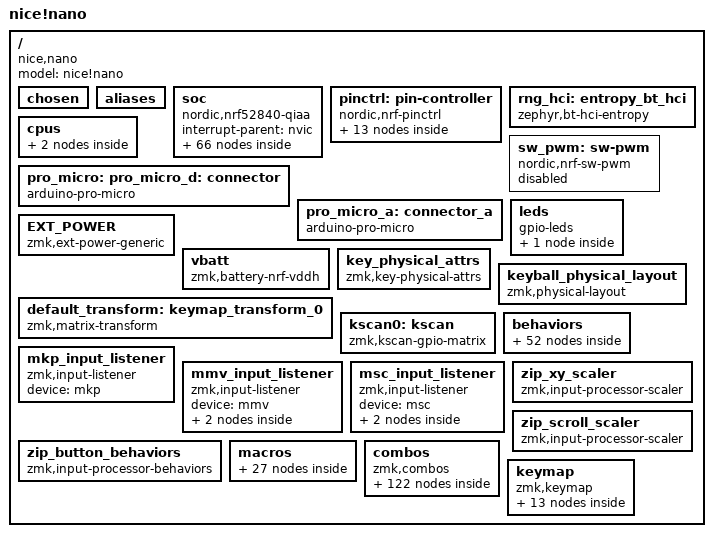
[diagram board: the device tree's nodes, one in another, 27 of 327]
/dts-v1/;

/ {
	#address-cells = < 0x1 >;
	#size-cells = < 0x1 >;
	model = "nice!nano";
	compatible = "nice,nano";
	chosen {
		zephyr,entropy = &rng;
		zephyr,flash-controller = &flash_controller;
		zephyr,code-partition = &code_partition;
		zephyr,sram = &sram0;
		zephyr,flash = &flash0;
		zmk,battery = &vbatt;
		zephyr,display = &oled;
		zmk,physical-layout = &keyball_physical_layout;
		zephyr,console = &snippet_zmk_usb_logging_uart;
		zephyr,shell-uart = &snippet_zmk_usb_logging_uart;
	};
	aliases {
	};
	soc {
		#address-cells = < 0x1 >;
		#size-cells = < 0x1 >;
		compatible = "nordic,nrf52840-qiaa", "nordic,nrf52840", "nordic,nrf52", "simple-bus";
		interrupt-parent = < &nvic >;
		ranges;
		nvic: interrupt-controller@e000e100 {
			#address-cells = < 0x1 >;
			compatible = "arm,v7m-nvic";
			reg = < 0xe000e100 0xc00 >;
			interrupt-controller;
			#interrupt-cells = < 0x2 >;
			arm,num-irq-priority-bits = < 0x3 >;
			phandle = < 0x1 >;
		};
		systick: timer@e000e010 {
			compatible = "arm,armv7m-systick";
			reg = < 0xe000e010 0x10 >;
			status = "disabled";
		};
		ficr: ficr@10000000 {
			compatible = "nordic,nrf-ficr";
			reg = < 0x10000000 0x1000 >;
			status = "okay";
		};
		uicr: uicr@10001000 {
			compatible = "nordic,nrf-uicr";
			reg = < 0x10001000 0x1000 >;
			status = "okay";
		};
		sram0: memory@20000000 {
			compatible = "mmio-sram";
			reg = < 0x20000000 0x40000 >;
		};
		clock: clock@40000000 {
			compatible = "nordic,nrf-clock";
			reg = < 0x40000000 0x1000 >;
			interrupts = < 0x0 0x1 >;
			status = "okay";
		};
		power: power@40000000 {
			compatible = "nordic,nrf-power";
			reg = < 0x40000000 0x1000 >;
			interrupts = < 0x0 0x1 >;
			status = "okay";
			#address-cells = < 0x1 >;
			#size-cells = < 0x1 >;
			gpregret1: gpregret1@4000051c {
				#address-cells = < 0x1 >;
				#size-cells = < 0x1 >;
				compatible = "nordic,nrf-gpregret";
				reg = < 0x4000051c 0x1 >;
				status = "okay";
			};
			gpregret2: gpregret2@40000520 {
				#address-cells = < 0x1 >;
				#size-cells = < 0x1 >;
				compatible = "nordic,nrf-gpregret";
				reg = < 0x40000520 0x1 >;
				status = "okay";
			};
		};
		radio: radio@40001000 {
			compatible = "nordic,nrf-radio";
			reg = < 0x40001000 0x1000 >;
			interrupts = < 0x1 0x1 >;
			status = "okay";
			ieee802154-supported;
			ble-2mbps-supported;
			ble-coded-phy-supported;
			tx-high-power-supported;
			ieee802154: ieee802154 {
				compatible = "nordic,nrf-ieee802154";
				status = "disabled";
			};
		};
		uart0: pro_micro_serial: uart@40002000 {
			compatible = "nordic,nrf-uarte";
			reg = < 0x40002000 0x1000 >;
			interrupts = < 0x2 0x1 >;
			status = "disabled";
			current-speed = < 0x1c200 >;
			pinctrl-0 = < &uart0_default >;
			pinctrl-1 = < &uart0_sleep >;
			pinctrl-names = "default", "sleep";
		};
		i2c0: pro_micro_i2c: i2c@40003000 {
			compatible = "nordic,nrf-twi";
			#address-cells = < 0x1 >;
			#size-cells = < 0x0 >;
			reg = < 0x40003000 0x1000 >;
			clock-frequency = < 0x186a0 >;
			interrupts = < 0x3 0x1 >;
			easydma-maxcnt-bits = < 0x10 >;
			status = "okay";
			pinctrl-0 = < &i2c0_default >;
			pinctrl-1 = < &i2c0_sleep >;
			pinctrl-names = "default", "sleep";
			oled: ssd1306@3c {
				compatible = "solomon,ssd1306fb";
				reg = < 0x3c >;
				width = < 0x80 >;
				height = < 0x20 >;
				segment-offset = < 0x0 >;
				page-offset = < 0x0 >;
				display-offset = < 0x0 >;
				multiplex-ratio = < 0x1f >;
				segment-remap;
				com-invdir;
				com-sequential;
				inversion-on;
				prechargep = < 0x22 >;
			};
		};
		spi0: spi@40003000 {
			compatible = "nordic,nrf-spim";
			#address-cells = < 0x1 >;
			#size-cells = < 0x0 >;
			reg = < 0x40003000 0x1000 >;
			interrupts = < 0x3 0x1 >;
			max-frequency = < 0x7a1200 >;
			easydma-maxcnt-bits = < 0x10 >;
			status = "disabled";
		};
		i2c1: i2c@40004000 {
			compatible = "nordic,nrf-twim";
			#address-cells = < 0x1 >;
			#size-cells = < 0x0 >;
			reg = < 0x40004000 0x1000 >;
			clock-frequency = < 0x186a0 >;
			interrupts = < 0x4 0x1 >;
			easydma-maxcnt-bits = < 0x10 >;
			status = "disabled";
		};
		spi1: pro_micro_spi: spi@40004000 {
			compatible = "nordic,nrf-spim";
			#address-cells = < 0x1 >;
			#size-cells = < 0x0 >;
			reg = < 0x40004000 0x1000 >;
			interrupts = < 0x4 0x1 >;
			max-frequency = < 0x7a1200 >;
			easydma-maxcnt-bits = < 0x10 >;
			status = "disabled";
			pinctrl-0 = < &spi1_default >;
			pinctrl-1 = < &spi1_sleep >;
			pinctrl-names = "default", "sleep";
		};
		nfct: nfct@40005000 {
			compatible = "nordic,nrf-nfct";
			reg = < 0x40005000 0x1000 >;
			interrupts = < 0x5 0x1 >;
			status = "okay";
		};
		gpiote: gpiote@40006000 {
			compatible = "nordic,nrf-gpiote";
			reg = < 0x40006000 0x1000 >;
			interrupts = < 0x6 0x5 >;
			status = "okay";
		};
		adc: adc@40007000 {
			compatible = "nordic,nrf-saadc";
			reg = < 0x40007000 0x1000 >;
			interrupts = < 0x7 0x1 >;
			status = "okay";
			#io-channel-cells = < 0x1 >;
		};
		timer0: timer@40008000 {
			compatible = "nordic,nrf-timer";
			status = "disabled";
			reg = < 0x40008000 0x1000 >;
			cc-num = < 0x4 >;
			max-bit-width = < 0x20 >;
			interrupts = < 0x8 0x1 >;
			prescaler = < 0x0 >;
		};
		timer1: timer@40009000 {
			compatible = "nordic,nrf-timer";
			status = "disabled";
			reg = < 0x40009000 0x1000 >;
			cc-num = < 0x4 >;
			max-bit-width = < 0x20 >;
			interrupts = < 0x9 0x1 >;
			prescaler = < 0x0 >;
			phandle = < 0x8 >;
		};
		timer2: timer@4000a000 {
			compatible = "nordic,nrf-timer";
			status = "disabled";
			reg = < 0x4000a000 0x1000 >;
			cc-num = < 0x4 >;
			max-bit-width = < 0x20 >;
			interrupts = < 0xa 0x1 >;
			prescaler = < 0x0 >;
		};
		rtc0: rtc@4000b000 {
			compatible = "nordic,nrf-rtc";
			reg = < 0x4000b000 0x1000 >;
			cc-num = < 0x3 >;
			interrupts = < 0xb 0x1 >;
			status = "disabled";
			clock-frequency = < 0x8000 >;
			prescaler = < 0x1 >;
		};
		temp: temp@4000c000 {
			compatible = "nordic,nrf-temp";
			reg = < 0x4000c000 0x1000 >;
			interrupts = < 0xc 0x1 >;
			status = "okay";
		};
		rng: random@4000d000 {
			compatible = "nordic,nrf-rng";
			reg = < 0x4000d000 0x1000 >;
			interrupts = < 0xd 0x1 >;
			status = "okay";
		};
		ecb: ecb@4000e000 {
			compatible = "nordic,nrf-ecb";
			reg = < 0x4000e000 0x1000 >;
			interrupts = < 0xe 0x1 >;
			status = "okay";
		};
		ccm: ccm@4000f000 {
			compatible = "nordic,nrf-ccm";
			reg = < 0x4000f000 0x1000 >;
			interrupts = < 0xf 0x1 >;
			length-field-length-8-bits;
			status = "okay";
		};
		wdt: wdt0: watchdog@40010000 {
			compatible = "nordic,nrf-wdt";
			reg = < 0x40010000 0x1000 >;
			interrupts = < 0x10 0x1 >;
			status = "okay";
		};
		rtc1: rtc@40011000 {
			compatible = "nordic,nrf-rtc";
			reg = < 0x40011000 0x1000 >;
			cc-num = < 0x4 >;
			interrupts = < 0x11 0x1 >;
			status = "disabled";
			clock-frequency = < 0x8000 >;
			prescaler = < 0x1 >;
		};
		qdec: qdec0: qdec@40012000 {
			compatible = "nordic,nrf-qdec";
			reg = < 0x40012000 0x1000 >;
			interrupts = < 0x12 0x1 >;
			status = "disabled";
		};
		comp: comparator@40013000 {
			compatible = "nordic,nrf-comp";
			reg = < 0x40013000 0x1000 >;
			interrupts = < 0x13 0x1 >;
			status = "disabled";
			#io-channel-cells = < 0x1 >;
		};
		egu0: swi0: egu@40014000 {
			compatible = "nordic,nrf-egu", "nordic,nrf-swi";
			reg = < 0x40014000 0x1000 >;
			interrupts = < 0x14 0x1 >;
			status = "okay";
		};
		egu1: swi1: egu@40015000 {
			compatible = "nordic,nrf-egu", "nordic,nrf-swi";
			reg = < 0x40015000 0x1000 >;
			interrupts = < 0x15 0x1 >;
			status = "okay";
		};
		egu2: swi2: egu@40016000 {
			compatible = "nordic,nrf-egu", "nordic,nrf-swi";
			reg = < 0x40016000 0x1000 >;
			interrupts = < 0x16 0x1 >;
			status = "okay";
		};
		egu3: swi3: egu@40017000 {
			compatible = "nordic,nrf-egu", "nordic,nrf-swi";
			reg = < 0x40017000 0x1000 >;
			interrupts = < 0x17 0x1 >;
			status = "okay";
		};
		egu4: swi4: egu@40018000 {
			compatible = "nordic,nrf-egu", "nordic,nrf-swi";
			reg = < 0x40018000 0x1000 >;
			interrupts = < 0x18 0x1 >;
			status = "okay";
		};
		egu5: swi5: egu@40019000 {
			compatible = "nordic,nrf-egu", "nordic,nrf-swi";
			reg = < 0x40019000 0x1000 >;
			interrupts = < 0x19 0x1 >;
			status = "okay";
		};
		timer3: timer@4001a000 {
			compatible = "nordic,nrf-timer";
			status = "disabled";
			reg = < 0x4001a000 0x1000 >;
			cc-num = < 0x6 >;
			max-bit-width = < 0x20 >;
			interrupts = < 0x1a 0x1 >;
			prescaler = < 0x0 >;
		};
		timer4: timer@4001b000 {
			compatible = "nordic,nrf-timer";
			status = "disabled";
			reg = < 0x4001b000 0x1000 >;
			cc-num = < 0x6 >;
			max-bit-width = < 0x20 >;
			interrupts = < 0x1b 0x1 >;
			prescaler = < 0x0 >;
		};
		pwm0: pwm@4001c000 {
			compatible = "nordic,nrf-pwm";
			reg = < 0x4001c000 0x1000 >;
			interrupts = < 0x1c 0x1 >;
			status = "disabled";
			#pwm-cells = < 0x3 >;
		};
		pdm0: pdm@4001d000 {
			compatible = "nordic,nrf-pdm";
			reg = < 0x4001d000 0x1000 >;
			interrupts = < 0x1d 0x1 >;
			status = "disabled";
		};
		acl: acl@4001e000 {
			compatible = "nordic,nrf-acl";
			reg = < 0x4001e000 0x1000 >;
			status = "okay";
		};
		flash_controller: flash-controller@4001e000 {
			compatible = "nordic,nrf52-flash-controller";
			reg = < 0x4001e000 0x1000 >;
			partial-erase;
			#address-cells = < 0x1 >;
			#size-cells = < 0x1 >;
			flash0: flash@0 {
				compatible = "soc-nv-flash";
				erase-block-size = < 0x1000 >;
				write-block-size = < 0x4 >;
				reg = < 0x0 0x100000 >;
				partitions {
					compatible = "fixed-partitions";
					#address-cells = < 0x1 >;
					#size-cells = < 0x1 >;
					sd_partition: partition@0 {
						reg = < 0x0 0x26000 >;
					};
					code_partition: partition@26000 {
						reg = < 0x26000 0xc6000 >;
					};
					storage_partition: partition@ec000 {
						reg = < 0xec000 0x8000 >;
					};
					boot_partition: partition@f4000 {
						reg = < 0xf4000 0xc000 >;
					};
				};
			};
		};
		ppi: ppi@4001f000 {
			compatible = "nordic,nrf-ppi";
			reg = < 0x4001f000 0x1000 >;
			status = "okay";
		};
		mwu: mwu@40020000 {
			compatible = "nordic,nrf-mwu";
			reg = < 0x40020000 0x1000 >;
			status = "okay";
		};
		pwm1: pwm@40021000 {
			compatible = "nordic,nrf-pwm";
			reg = < 0x40021000 0x1000 >;
			interrupts = < 0x21 0x1 >;
			status = "disabled";
			#pwm-cells = < 0x3 >;
		};
		pwm2: pwm@40022000 {
			compatible = "nordic,nrf-pwm";
			reg = < 0x40022000 0x1000 >;
			interrupts = < 0x22 0x1 >;
			status = "disabled";
			#pwm-cells = < 0x3 >;
		};
		spi2: spi@40023000 {
			compatible = "nordic,nrf-spim";
			#address-cells = < 0x1 >;
			#size-cells = < 0x0 >;
			reg = < 0x40023000 0x1000 >;
			interrupts = < 0x23 0x1 >;
			max-frequency = < 0x7a1200 >;
			easydma-maxcnt-bits = < 0x10 >;
			status = "disabled";
		};
		rtc2: rtc@40024000 {
			compatible = "nordic,nrf-rtc";
			reg = < 0x40024000 0x1000 >;
			cc-num = < 0x4 >;
			interrupts = < 0x24 0x1 >;
			status = "disabled";
			clock-frequency = < 0x8000 >;
			prescaler = < 0x1 >;
		};
		i2s0: i2s@40025000 {
			compatible = "nordic,nrf-i2s";
			#address-cells = < 0x1 >;
			#size-cells = < 0x0 >;
			reg = < 0x40025000 0x1000 >;
			interrupts = < 0x25 0x1 >;
			status = "disabled";
		};
		usbd: zephyr_udc0: usbd@40027000 {
			compatible = "nordic,nrf-usbd";
			reg = < 0x40027000 0x1000 >;
			interrupts = < 0x27 0x1 >;
			num-bidir-endpoints = < 0x1 >;
			num-in-endpoints = < 0x7 >;
			num-out-endpoints = < 0x7 >;
			num-isoin-endpoints = < 0x1 >;
			num-isoout-endpoints = < 0x1 >;
			status = "okay";
			snippet_zmk_usb_logging_uart: snippet_zmk_usb_logging_uart {
				compatible = "zephyr,cdc-acm-uart";
			};
		};
		uart1: uart@40028000 {
			compatible = "nordic,nrf-uarte";
			reg = < 0x40028000 0x1000 >;
			interrupts = < 0x28 0x1 >;
			status = "disabled";
		};
		qspi: qspi@40029000 {
			compatible = "nordic,nrf-qspi";
			#address-cells = < 0x1 >;
			#size-cells = < 0x0 >;
			reg = < 0x40029000 0x1000 >, < 0x12000000 0x8000000 >;
			reg-names = "qspi", "qspi_mm";
			interrupts = < 0x29 0x1 >;
			status = "disabled";
		};
		pwm3: pwm@4002d000 {
			compatible = "nordic,nrf-pwm";
			reg = < 0x4002d000 0x1000 >;
			interrupts = < 0x2d 0x1 >;
			status = "disabled";
			#pwm-cells = < 0x3 >;
		};
		spi3: spi@4002f000 {
			compatible = "nordic,nrf-spim";
			#address-cells = < 0x1 >;
			#size-cells = < 0x0 >;
			reg = < 0x4002f000 0x1000 >;
			interrupts = < 0x2f 0x1 >;
			max-frequency = < 0x1e84800 >;
			easydma-maxcnt-bits = < 0x10 >;
			rx-delay-supported;
			rx-delay = < 0x2 >;
			status = "disabled";
		};
		gpio0: gpio@50000000 {
			compatible = "nordic,nrf-gpio";
			gpio-controller;
			reg = < 0x50000000 0x200 0x50000500 0x300 >;
			#gpio-cells = < 0x2 >;
			status = "okay";
			port = < 0x0 >;
			phandle = < 0x9 >;
		};
		gpio1: gpio@50000300 {
			compatible = "nordic,nrf-gpio";
			gpio-controller;
			reg = < 0x50000300 0x200 0x50000800 0x300 >;
			#gpio-cells = < 0x2 >;
			ngpios = < 0x10 >;
			status = "okay";
			port = < 0x1 >;
			phandle = < 0xa >;
		};
		cryptocell: crypto@5002a000 {
			compatible = "nordic,cryptocell", "arm,cryptocell-310";
			reg = < 0x5002a000 0x1000 >, < 0x5002b000 0x1000 >;
			reg-names = "wrapper", "core";
			interrupts = < 0x2a 0x1 >;
			status = "disabled";
		};
	};
	pinctrl: pin-controller {
		compatible = "nordic,nrf-pinctrl";
		uart0_default: uart0_default {
			phandle = < 0x2 >;
			group1 {
				psels = < 0x10008 >;
				bias-pull-up;
			};
			group2 {
				psels = < 0x6 >;
			};
		};
		uart0_sleep: uart0_sleep {
			phandle = < 0x3 >;
			group1 {
				psels = < 0x10008 >, < 0x6 >;
				low-power-enable;
			};
		};
		i2c0_default: i2c0_default {
			phandle = < 0x4 >;
			group1 {
				psels = < 0xc0011 >, < 0xb0014 >;
			};
		};
		i2c0_sleep: i2c0_sleep {
			phandle = < 0x5 >;
			group1 {
				psels = < 0xc0011 >, < 0xb0014 >;
				low-power-enable;
			};
		};
		spi1_default: spi1_default {
			phandle = < 0x6 >;
			group1 {
				psels = < 0x4002d >, < 0x5000a >, < 0x6002b >;
			};
		};
		spi1_sleep: spi1_sleep {
			phandle = < 0x7 >;
			group1 {
				psels = < 0x4002d >, < 0x5000a >, < 0x6002b >;
				low-power-enable;
			};
		};
	};
	rng_hci: entropy_bt_hci {
		compatible = "zephyr,bt-hci-entropy";
		status = "okay";
	};
	sw_pwm: sw-pwm {
		compatible = "nordic,nrf-sw-pwm";
		status = "disabled";
		generator = < &timer1 >;
		clock-prescaler = < 0x0 >;
		#pwm-cells = < 0x3 >;
	};
	cpus {
		#address-cells = < 0x1 >;
		#size-cells = < 0x0 >;
		cpu@0 {
			device_type = "cpu";
			compatible = "arm,cortex-m4f";
			reg = < 0x0 >;
			#address-cells = < 0x1 >;
			#size-cells = < 0x1 >;
			itm: itm@e0000000 {
				compatible = "arm,armv7m-itm";
				reg = < 0xe0000000 0x1000 >;
				swo-ref-frequency = < 0x1e84800 >;
			};
		};
	};
	pro_micro: pro_micro_d: connector {
		compatible = "arduino-pro-micro";
		#gpio-cells = < 0x2 >;
		gpio-map-mask = < 0xffffffff 0xffffffc0 >;
		gpio-map-pass-thru = < 0x0 0x3f >;
		gpio-map = < 0x0 0x0 &gpio0 0x8 0x0 >, < 0x1 0x0 &gpio0 0x6 0x0 >, < 0x2 0x0 &gpio0 0x11 0x0 >, < 0x3 0x0 &gpio0 0x14 0x0 >, < 0x4 0x0 &gpio0 0x16 0x0 >, < 0x5 0x0 &gpio0 0x18 0x0 >, < 0x6 0x0 &gpio1 0x0 0x0 >, < 0x7 0x0 &gpio0 0xb 0x0 >, < 0x8 0x0 &gpio1 0x4 0x0 >, < 0x9 0x0 &gpio1 0x6 0x0 >, < 0xa 0x0 &gpio0 0x9 0x0 >, < 0x10 0x0 &gpio0 0xa 0x0 >, < 0xe 0x0 &gpio1 0xb 0x0 >, < 0xf 0x0 &gpio1 0xd 0x0 >, < 0x12 0x0 &gpio1 0xf 0x0 >, < 0x13 0x0 &gpio0 0x2 0x0 >, < 0x14 0x0 &gpio0 0x1d 0x0 >, < 0x15 0x0 &gpio0 0x1f 0x0 >;
		phandle = < 0xe >;
	};
	pro_micro_a: connector_a {
		compatible = "arduino-pro-micro";
		#gpio-cells = < 0x2 >;
		gpio-map-mask = < 0xffffffff 0xffffffc0 >;
		gpio-map-pass-thru = < 0x0 0x3f >;
		gpio-map = < 0x0 0x0 &gpio1 0xf 0x0 >, < 0x1 0x0 &gpio0 0x2 0x0 >, < 0x2 0x0 &gpio0 0x1d 0x0 >, < 0x3 0x0 &gpio0 0x1f 0x0 >, < 0x6 0x0 &gpio0 0x16 0x0 >, < 0x7 0x0 &gpio1 0x0 0x0 >, < 0x8 0x0 &gpio1 0x4 0x0 >, < 0x9 0x0 &gpio1 0x6 0x0 >, < 0xa 0x0 &gpio0 0x9 0x0 >;
	};
	leds {
		compatible = "gpio-leds";
		blue_led: led_0 {
			gpios = < &gpio0 0xf 0x0 >;
		};
	};
	EXT_POWER {
		compatible = "zmk,ext-power-generic";
		control-gpios = < &gpio0 0xd 0x0 >;
		init-delay-ms = < 0x32 >;
	};
	vbatt: vbatt {
		compatible = "zmk,battery-nrf-vddh";
	};
	key_physical_attrs: key_physical_attrs {
		compatible = "zmk,key-physical-attrs";
		#key-cells = < 0x7 >;
		phandle = < 0xd >;
	};
	keyball_physical_layout: keyball_physical_layout {
		compatible = "zmk,physical-layout";
		display-name = "Default";
		transform = < &default_transform >;
		kscan = < &kscan0 >;
		keys = < &key_physical_attrs 0x64 0x64 0x0 0x26 0x0 0x0 0x0 >, < &key_physical_attrs 0x64 0x64 0x64 0xd 0x0 0x0 0x0 >, < &key_physical_attrs 0x64 0x64 0xc8 0x0 0x0 0x0 0x0 >, < &key_physical_attrs 0x64 0x64 0x12c 0xd 0x0 0x0 0x0 >, < &key_physical_attrs 0x64 0x64 0x190 0x19 0x0 0x0 0x0 >, < &key_physical_attrs 0x64 0x64 0x352 0x19 0x0 0x0 0x0 >, < &key_physical_attrs 0x64 0x64 0x3b6 0xd 0x0 0x0 0x0 >, < &key_physical_attrs 0x64 0x64 0x41a 0x0 0x0 0x0 0x0 >, < &key_physical_attrs 0x64 0x64 0x47e 0xd 0x0 0x0 0x0 >, < &key_physical_attrs 0x64 0x64 0x4e2 0x26 0x0 0x0 0x0 >, < &key_physical_attrs 0x64 0x64 0x0 0x8a 0x0 0x0 0x0 >, < &key_physical_attrs 0x64 0x64 0x64 0x71 0x0 0x0 0x0 >, < &key_physical_attrs 0x64 0x64 0xc8 0x64 0x0 0x0 0x0 >, < &key_physical_attrs 0x64 0x64 0x12c 0x71 0x0 0x0 0x0 >, < &key_physical_attrs 0x64 0x64 0x190 0x7d 0x0 0x0 0x0 >, < &key_physical_attrs 0x64 0x64 0x352 0x7d 0x0 0x0 0x0 >, < &key_physical_attrs 0x64 0x64 0x3b6 0x71 0x0 0x0 0x0 >, < &key_physical_attrs 0x64 0x64 0x41a 0x64 0x0 0x0 0x0 >, < &key_physical_attrs 0x64 0x64 0x47e 0x71 0x0 0x0 0x0 >, < &key_physical_attrs 0x64 0x64 0x4e2 0x8a 0x0 0x0 0x0 >, < &key_physical_attrs 0x64 0x64 0x0 0xee 0x0 0x0 0x0 >, < &key_physical_attrs 0x64 0x64 0x64 0xd5 0x0 0x0 0x0 >, < &key_physical_attrs 0x64 0x64 0xc8 0xc8 0x0 0x0 0x0 >, < &key_physical_attrs 0x64 0x64 0x12c 0xd5 0x0 0x0 0x0 >, < &key_physical_attrs 0x64 0x64 0x190 0xe1 0x0 0x0 0x0 >, < &key_physical_attrs 0x64 0x64 0x352 0xe1 0x0 0x0 0x0 >, < &key_physical_attrs 0x64 0x64 0x3b6 0xd5 0x0 0x0 0x0 >, < &key_physical_attrs 0x64 0x64 0x41a 0xc8 0x0 0x0 0x0 >, < &key_physical_attrs 0x64 0x64 0x47e 0xd5 0x0 0x0 0x0 >, < &key_physical_attrs 0x64 0x64 0x4e2 0xee 0x0 0x0 0x0 >, < &key_physical_attrs 0x64 0x64 0x0 0x152 0x0 0x0 0x0 >, < &key_physical_attrs 0x64 0x64 0x64 0x139 0x0 0x0 0x0 >, < &key_physical_attrs 0x64 0x64 0xc8 0x12c 0x0 0x0 0x0 >, < &key_physical_attrs 0x64 0x64 0x145 0x15e 0x0 0x0 0x0 >, < &key_physical_attrs 0x64 0x64 0x1fe 0x104 0x3e8 0xffffffce 0xffffff9c >, < &key_physical_attrs 0x64 0x64 0x46 0xd2 0x9c4 0xffffffce 0x578 >, < &key_physical_attrs 0x64 0x64 0x44c 0x36b 0xfffff5d8 0xffffffce 0x578 >, < &key_physical_attrs 0x64 0x64 0x307 0x20d 0xfffffc18 0xffffffce 0xffffff9c >, < &key_physical_attrs 0x64 0x64 0x4e2 0x152 0x0 0x0 0x0 >;
	};
	default_transform: keymap_transform_0 {
		compatible = "zmk,matrix-transform";
		columns = < 0xc >;
		rows = < 0x4 >;
		map = < 0x0 0x1 0x2 0x3 0x4 0xa 0x9 0x8 0x7 0x6 0x100 0x101 0x102 0x103 0x104 0x10a 0x109 0x108 0x107 0x106 0x200 0x201 0x202 0x203 0x204 0x20a 0x209 0x208 0x207 0x206 0x300 0x301 0x302 0x303 0x304 0x305 0x30b 0x30a 0x306 >;
		phandle = < 0xb >;
	};
	kscan0: kscan {
		compatible = "zmk,kscan-gpio-matrix";
		label = "KSCAN";
		diode-direction = "col2row";
		row-gpios = < &pro_micro 0x15 0x20 >, < &pro_micro 0x14 0x20 >, < &pro_micro 0x13 0x20 >, < &pro_micro 0x12 0x20 >;
		col-gpios = < &pro_micro 0x4 0x0 >, < &pro_micro 0x5 0x0 >, < &pro_micro 0x6 0x0 >, < &pro_micro 0x7 0x0 >, < &pro_micro 0x8 0x0 >, < &pro_micro 0x9 0x0 >;
		phandle = < 0xc >;
	};
	behaviors {
		mkp: mouse_key_press {
			compatible = "zmk,behavior-mouse-key-press";
			#binding-cells = < 0x1 >;
			display-name = "Mouse Key Press";
			phandle = < 0x21 >;
		};
		mmv: mouse_move {
			compatible = "zmk,behavior-input-two-axis";
			#binding-cells = < 0x1 >;
			x-input-code = < 0x0 >;
			y-input-code = < 0x1 >;
			time-to-max-speed-ms = < 0x1f4 >;
			acceleration-exponent = < 0x1 >;
			delay-ms = < 0x0 >;
			phandle = < 0x22 >;
		};
		msc: mouse_scroll {
			compatible = "zmk,behavior-input-two-axis";
			#binding-cells = < 0x1 >;
			x-input-code = < 0x6 >;
			y-input-code = < 0x8 >;
			time-to-max-speed-ms = < 0x12c >;
			acceleration-exponent = < 0x0 >;
			delay-ms = < 0x0 >;
			phandle = < 0x24 >;
		};
		kp: key_press {
			compatible = "zmk,behavior-key-press";
			#binding-cells = < 0x1 >;
			display-name = "Key Press";
			phandle = < 0xf >;
		};
		trans: transparent {
			compatible = "zmk,behavior-transparent";
			#binding-cells = < 0x0 >;
			display-name = "Transparent";
			phandle = < 0x42 >;
		};
		none: none {
			compatible = "zmk,behavior-none";
			#binding-cells = < 0x0 >;
			display-name = "None";
			phandle = < 0x20 >;
		};
		sk: sticky_key {
			compatible = "zmk,behavior-sticky-key";
			#binding-cells = < 0x1 >;
			release-after-ms = < 0x3e8 >;
			bindings = < &kp >;
			ignore-modifiers;
			display-name = "Sticky Key";
			phandle = < 0x2c >;
		};
		sl: sticky_layer {
			compatible = "zmk,behavior-sticky-key";
			#binding-cells = < 0x1 >;
			release-after-ms = < 0x3e8 >;
			bindings = < &mo >;
			quick-release;
			display-name = "Sticky Layer";
			phandle = < 0x1a >;
		};
		mo: momentary_layer {
			compatible = "zmk,behavior-momentary-layer";
			#binding-cells = < 0x1 >;
			display-name = "Momentary Layer";
			phandle = < 0x10 >;
		};
		sys_reset: sysreset {
			compatible = "zmk,behavior-reset";
			#binding-cells = < 0x0 >;
			display-name = "Reset";
			phandle = < 0x50 >;
		};
		bootloader: bootload {
			compatible = "zmk,behavior-reset";
			type = < 0x57 >;
			#binding-cells = < 0x0 >;
			display-name = "Bootloader";
		};
		rgb_ug: rgb_ug {
			compatible = "zmk,behavior-rgb-underglow";
			#binding-cells = < 0x2 >;
			display-name = "Underglow";
		};
		bt: bluetooth {
			compatible = "zmk,behavior-bluetooth";
			#binding-cells = < 0x2 >;
			display-name = "Bluetooth";
			phandle = < 0x30 >;
		};
		ext_power: extpower {
			compatible = "zmk,behavior-ext-power";
			#binding-cells = < 0x1 >;
			display-name = "External Power";
		};
		out: outputs {
			compatible = "zmk,behavior-outputs";
			#binding-cells = < 0x1 >;
			display-name = "Output Selection";
			phandle = < 0x12 >;
		};
		caps_word: caps_word {
			compatible = "zmk,behavior-caps-word";
			#binding-cells = < 0x0 >;
			continue-list = < 0x207002d 0x7002d >;
			display-name = "Caps Word";
			phandle = < 0x3b >;
		};
		macro_tap: macro_tap {
			compatible = "zmk,macro-control-mode-tap";
			#binding-cells = < 0x0 >;
			phandle = < 0x27 >;
		};
		macro_press: macro_press {
			compatible = "zmk,macro-control-mode-press";
			#binding-cells = < 0x0 >;
			phandle = < 0x2b >;
		};
		macro_release: macro_release {
			compatible = "zmk,macro-control-mode-release";
			#binding-cells = < 0x0 >;
			phandle = < 0x2e >;
		};
		macro_tap_time: macro_tap_time {
			compatible = "zmk,macro-control-tap-time";
			#binding-cells = < 0x1 >;
			phandle = < 0x26 >;
		};
		macro_wait_time: macro_wait_time {
			compatible = "zmk,macro-control-wait-time";
			#binding-cells = < 0x1 >;
			phandle = < 0x2f >;
		};
		macro_pause_for_release: macro_pause_for_release {
			compatible = "zmk,macro-pause-for-release";
			#binding-cells = < 0x0 >;
			phandle = < 0x2d >;
		};
		macro_param_1to1: macro_param_1to1 {
			compatible = "zmk,macro-param-1to1";
			#binding-cells = < 0x0 >;
			phandle = < 0x28 >;
		};
		macro_param_1to2: macro_param_1to2 {
			compatible = "zmk,macro-param-1to2";
			#binding-cells = < 0x0 >;
			phandle = < 0x37 >;
		};
		macro_param_2to1: macro_param_2to1 {
			compatible = "zmk,macro-param-2to1";
			#binding-cells = < 0x0 >;
			phandle = < 0x29 >;
		};
		macro_param_2to2: macro_param_2to2 {
			compatible = "zmk,macro-param-2to2";
			#binding-cells = < 0x0 >;
		};
		studio_unlock: studio_unlock {
			compatible = "zmk,behavior-studio-unlock";
			#binding-cells = < 0x0 >;
			display-name = "Studio Unlock";
		};
		hml: home_row_mod_left {
			compatible = "zmk,behavior-hold-tap";
			#binding-cells = < 0x2 >;
			flavor = "balanced";
			tapping-term-ms = < 0x140 >;
			quick-tap-ms = < 0xaf >;
			require-prior-idle-ms = < 0xfa >;
			bindings = < &kp >, < &kp >;
			hold-trigger-key-positions = < 0x5 0x6 0x7 0x8 0x9 0xf 0x10 0x11 0x12 0x13 0x19 0x1a 0x1b 0x1c 0x1d 0x1e 0x1f 0x20 0x21 0x22 0x23 0x24 0x25 0x26 >;
			hold-trigger-on-release;
			phandle = < 0x40 >;
		};
		hmr: home_row_mod_right {
			compatible = "zmk,behavior-hold-tap";
			#binding-cells = < 0x2 >;
			flavor = "balanced";
			tapping-term-ms = < 0x140 >;
			quick-tap-ms = < 0xaf >;
			require-prior-idle-ms = < 0xfa >;
			bindings = < &kp >, < &kp >;
			hold-trigger-key-positions = < 0x0 0x1 0x2 0x3 0x4 0xa 0xb 0xc 0xd 0xe 0x14 0x15 0x16 0x17 0x18 0x1e 0x1f 0x20 0x21 0x22 0x23 0x24 0x25 0x26 >;
			hold-trigger-on-release;
			phandle = < 0x41 >;
		};
		bt_0: bt_0 {
			compatible = "zmk,behavior-tap-dance";
			label = "BT_0";
			#binding-cells = < 0x0 >;
			tapping-term-ms = < 0x3e8 >;
			bindings = < &bt_select_disc_0 >, < &out 0x1 >, < &bt_pairing_c 0x0 >;
			phandle = < 0x4b >;
		};
		bt_1: bt_1 {
			compatible = "zmk,behavior-tap-dance";
			label = "BT_1";
			#binding-cells = < 0x0 >;
			tapping-term-ms = < 0x3e8 >;
			bindings = < &bt_select_disc_1 >, < &out 0x1 >, < &bt_pairing_c 0x1 >;
			phandle = < 0x4c >;
		};
		bt_2: bt_2 {
			compatible = "zmk,behavior-tap-dance";
			label = "BT_2";
			#binding-cells = < 0x0 >;
			tapping-term-ms = < 0x3e8 >;
			bindings = < &bt_select_disc_2 >, < &out 0x1 >, < &bt_pairing_c 0x2 >;
			phandle = < 0x4d >;
		};
		bt_3: bt_3 {
			compatible = "zmk,behavior-tap-dance";
			label = "BT_3";
			#binding-cells = < 0x0 >;
			tapping-term-ms = < 0x3e8 >;
			bindings = < &bt_select_disc_3 >, < &out 0x1 >, < &bt_pairing_c 0x3 >;
			phandle = < 0x4e >;
		};
		bt_4: bt_4 {
			compatible = "zmk,behavior-tap-dance";
			label = "BT_4";
			#binding-cells = < 0x0 >;
			tapping-term-ms = < 0x3e8 >;
			bindings = < &bt_select_disc_4 >, < &out 0x1 >, < &bt_pairing_c 0x4 >;
			phandle = < 0x4f >;
		};
		tog_on: toggle_layer_on_only {
			compatible = "zmk,behavior-toggle-layer";
			#binding-cells = < 0x1 >;
			display-name = "Toggle Layer On";
			toggle-mode = "on";
			phandle = < 0x39 >;
		};
		tog_off: toggle_layer_off_only {
			compatible = "zmk,behavior-toggle-layer";
			#binding-cells = < 0x1 >;
			display-name = "Toggle Layer Off";
			toggle-mode = "off";
			phandle = < 0x38 >;
		};
		tdSelectCoppingLR: tdSelectCoppingLR {
			compatible = "zmk,behavior-hold-tap";
			#binding-cells = < 0x2 >;
			tapping_term_ms = < 0xc8 >;
			quick_tap_ms = < 0x0 >;
			flavor = "tap-preferred";
			bindings = < &scl_l_to_r >, < &scw_l_to_r >;
			phandle = < 0x4a >;
		};
		lrlMo: lrlMo {
			compatible = "zmk,behavior-hold-tap";
			label = "LRLMO";
			bindings = < &kp >, < &kp >;
			#binding-cells = < 0x2 >;
			flavor = "balanced";
			tapping-term-ms = < 0xdc >;
			quick-tap-ms = < 0xaf >;
			phandle = < 0x3f >;
		};
		lrDl: lrDl {
			compatible = "zmk,behavior-hold-tap";
			label = "LRDL";
			bindings = < &kp >, < &kp >;
			#binding-cells = < 0x2 >;
			flavor = "balanced";
			require-prior-idle-ms = < 0x78 >;
			tapping-term-ms = < 0xdc >;
			quick-tap-ms = < 0xaf >;
		};
		lrrMo: lrrMo {
			compatible = "zmk,behavior-hold-tap";
			label = "LRRMO";
			bindings = < &kp >, < &kp >;
			#binding-cells = < 0x2 >;
			tapping-term-ms = < 0xdc >;
			quick-tap-ms = < 0xaf >;
			phandle = < 0x49 >;
		};
		base_th_mo_kp_hp: base_th_mo_kp_hp {
			compatible = "zmk,behavior-hold-tap";
			flavor = "hold-preferred";
			tapping-term-ms = < 0xdc >;
			hold-trigger-on-release;
			#binding-cells = < 0x2 >;
			bindings = < &mo >, < &kp >;
			phandle = < 0x44 >;
		};
		th_mo_kp_hp: th_mo_kp_hp {
			compatible = "zmk,behavior-hold-tap";
			flavor = "hold-preferred";
			tapping-term-ms = < 0xdc >;
			quick-tap-ms = < 0xbe >;
			hold-trigger-on-release;
			#binding-cells = < 0x2 >;
			bindings = < &mo >, < &kp >;
			phandle = < 0x47 >;
		};
		th_kp_kp_hp: th_kp_kp_hp {
			compatible = "zmk,behavior-hold-tap";
			flavor = "hold-preferred";
			tapping-term-ms = < 0xdc >;
			quick-tap-ms = < 0xbe >;
			#binding-cells = < 0x2 >;
			hold-trigger-on-release;
			bindings = < &kp >, < &kp >;
			phandle = < 0x46 >;
		};
		space: space {
			compatible = "zmk,behavior-hold-tap";
			flavor = "balanced";
			tapping-term-ms = < 0xdc >;
			#binding-cells = < 0x2 >;
			require-prior-idle-ms = < 0x50 >;
			bindings = < &mo >, < &kp >;
			phandle = < 0x48 >;
		};
		spacelm: thumb_layer_access_spacebarlm {
			compatible = "zmk,behavior-hold-tap";
			flavor = "balanced";
			tapping-term-ms = < 0xdc >;
			#binding-cells = < 0x2 >;
			require-prior-idle-ms = < 0x50 >;
			bindings = < &mo >, < &kp >;
			phandle = < 0x45 >;
		};
		th_kp_sl_hp: th_kp_sl_hp {
			compatible = "zmk,behavior-hold-tap";
			#binding-cells = < 0x2 >;
			tapping-term-ms = < 0xc8 >;
			flavor = "hold-preferred";
			bindings = < &kp >, < &sl >;
		};
		lm_homerow: lm_homerow {
			compatible = "zmk,behavior-hold-tap";
			flavor = "hold-preferred";
			tapping-term-ms = < 0xdc >;
			#binding-cells = < 0x2 >;
			bindings = < &mhr >, < &kp >;
		};
		lm_homerow_short: lm_homerow_short {
			compatible = "zmk,behavior-hold-tap";
			flavor = "hold-preferred";
			tapping-term-ms = < 0x96 >;
			#binding-cells = < 0x2 >;
			bindings = < &mhr >, < &kp >;
			phandle = < 0x43 >;
		};
		tdSelectCoppingRL: tdSelectCoppingRL {
			compatible = "zmk,behavior-hold-tap";
			#binding-cells = < 0x2 >;
			tapping_term_ms = < 0xc8 >;
			quick_tap_ms = < 0x0 >;
			flavor = "tap-preferred";
			bindings = < &scl_r_to_l >, < &scw_r_to_l >;
		};
		td_find_s_ht: td_find_s_ht {
			compatible = "zmk,behavior-hold-tap";
			#binding-cells = < 0x2 >;
			tapping_term_ms = < 0xc8 >;
			quick_tap_ms = < 0x0 >;
			flavor = "tap-preferred";
			bindings = < &pfind >, < &kp >;
			phandle = < 0x3d >;
		};
		td_find_g_ht: td_find_g_ht {
			compatible = "zmk,behavior-hold-tap";
			#binding-cells = < 0x2 >;
			tapping_term_ms = < 0xc8 >;
			quick_tap_ms = < 0x0 >;
			flavor = "tap-preferred";
			bindings = < &gpfind >, < &kp >;
			phandle = < 0x3e >;
		};
		nav_esc: nav_esc {
			compatible = "zmk,behavior-tap-dance";
			label = "NAV_ESC";
			#binding-cells = < 0x0 >;
			tapping-term-ms = < 0x1f4 >;
			bindings = < &mo 0x4 >, < &none >, < &kp 0x70029 >;
		};
	};
	mkp_input_listener: mkp_input_listener {
		compatible = "zmk,input-listener";
		device = < &mkp >;
	};
	mmv_input_listener: mmv_input_listener {
		compatible = "zmk,input-listener";
		device = < &mmv >;
		warp {
			layers = < 0x4 >;
			input-processors = < &zip_xy_scaler 0x3 0x1 >;
		};
		precision {
			layers = < 0x3 >;
			input-processors = < &zip_xy_scaler 0x1 0x2 >;
		};
	};
	msc_input_listener: msc_input_listener {
		compatible = "zmk,input-listener";
		device = < &msc >;
		warp {
			layers = < 0x4 >;
			input-processors = < &zip_scroll_scaler 0x2 0x1 >;
		};
		precision {
			layers = < 0x3 >;
			input-processors = < &zip_scroll_scaler 0x1 0x2 >;
		};
	};
	zip_xy_scaler: zip_xy_scaler {
		compatible = "zmk,input-processor-scaler";
		#input-processor-cells = < 0x2 >;
		type = < 0x2 >;
		codes = < 0x0 0x1 >;
		track-remainders;
		phandle = < 0x23 >;
	};
	zip_scroll_scaler: zip_scroll_scaler {
		compatible = "zmk,input-processor-scaler";
		#input-processor-cells = < 0x2 >;
		type = < 0x2 >;
		codes = < 0x8 0x6 >;
		track-remainders;
		phandle = < 0x25 >;
	};
	zip_button_behaviors: zip_button_behaviors {
		compatible = "zmk,input-processor-behaviors";
		#input-processor-cells = < 0x0 >;
		codes = < 0x100 0x101 0x102 >;
		bindings = < &none &none &none >;
	};
	macros {
		mc_sleep: mc_sleep {
			compatible = "zmk,behavior-macro";
			#binding-cells = < 0x0 >;
			bindings = < &macro_tap_time 0x3e8 >, < &kp 0x9070014 >, < &macro_tap_time 0x14 >, < &kp 0x70029 >;
		};
		mc_bkctilde: mc_bkctilde {
			label = "&TILDE";
			compatible = "zmk,behavior-macro-one-param";
			#binding-cells = < 0x1 >;
			bindings = < &kp 0x4070008 >, < &macro_tap >, < &macro_param_1to1 &kp 0x0 >;
			phandle = < 0x3a >;
		};
		mc_tilde: mc_tilde {
			compatible = "zmk,behavior-macro-two-param";
			wait-ms = < 0x0 >;
			tap-ms = < 0x0 >;
			#binding-cells = < 0x2 >;
			bindings = < &macro_tap >, < &macro_param_1to1 &mo 0x0 >, < &macro_param_2to1 &kp 0x0 >;
		};
		mc_enne: mc_enne {
			label = "&ENNE";
			compatible = "zmk,behavior-macro-one-param";
			#binding-cells = < 0x1 >;
			bindings = < &macro_tap >, < &kp 0x4070011 &macro_param_1to1 &kp 0x0 >;
			phandle = < 0x2a >;
		};
		mc_ennesd: mac_enne_shift_delete {
			compatible = "zmk,behavior-macro-one-param";
			wait-ms = < 0x0 >;
			tap-ms = < 0x0 >;
			#binding-cells = < 0x1 >;
			bindings = < &macro_tap >, < &macro_param_1to1 &mc_enne 0x0 >;
			phandle = < 0x3c >;
		};
		mc_quesd: mc_quesd {
			compatible = "zmk,behavior-macro";
			wait-ms = < 0x0 >;
			tap-ms = < 0x0 >;
			#binding-cells = < 0x0 >;
			bindings = < &macro_tap >, < &kp 0x6070038 >, < &macro_press >, < &sk 0x700e1 >, < &macro_pause_for_release >, < &macro_release >, < &sk 0x700e1 >;
		};
		mhr: mhr {
			compatible = "zmk,behavior-macro-one-param";
			wait-ms = < 0x0 >;
			tap-ms = < 0x0 >;
			#binding-cells = < 0x1 >;
			bindings = < &macro_press >, < &mo 0x7 &macro_param_1to1 >, < &macro_press >, < &kp 0x0 >, < &macro_pause_for_release >, < &macro_param_1to1 >, < &macro_release >, < &kp 0x0 >, < &macro_release >, < &mo 0x7 >;
			phandle = < 0x1b >;
		};
		scl_l_to_r: scl_l_to_r {
			label = "&SCL_L_TO_R";
			compatible = "zmk,behavior-macro";
			#binding-cells = < 0x0 >;
			bindings = < &macro_tap >, < &kp 0x8070050 >, < &macro_wait_time 0x5 >, < &macro_tap >, < &kp 0xa07004f >, < &macro_wait_time 0x5 >, < &macro_tap >, < &kp 0x8070006 >;
			phandle = < 0x18 >;
		};
		scl_r_to_l: scl_r_to_l {
			label = "&SCL_R_TO_L";
			compatible = "zmk,behavior-macro";
			#binding-cells = < 0x0 >;
			bindings = < &macro_tap >, < &kp 0x807004f >, < &macro_wait_time 0x5 >, < &macro_tap >, < &kp 0xa070050 >, < &macro_wait_time 0x5 >, < &macro_tap >, < &kp 0x8070006 >;
			phandle = < 0x1c >;
		};
		scw_r_to_l: scw_r_to_l {
			label = "&SCW_R_TO_L";
			compatible = "zmk,behavior-macro";
			#binding-cells = < 0x0 >;
			bindings = < &macro_tap >, < &kp 0x407004f >, < &macro_wait_time 0x5 >, < &macro_tap >, < &kp 0x6070050 >, < &macro_wait_time 0x5 >, < &macro_tap >, < &kp 0x8070006 >;
			phandle = < 0x1d >;
		};
		scw_l_to_r: scw_l_to_r {
			label = "&SCW_L_TO_R";
			compatible = "zmk,behavior-macro";
			#binding-cells = < 0x0 >;
			bindings = < &macro_tap >, < &kp 0x4070050 >, < &macro_wait_time 0x5 >, < &macro_tap >, < &kp 0x607004f >, < &macro_wait_time 0x5 >, < &macro_tap >, < &kp 0x8070006 >;
			phandle = < 0x19 >;
		};
		scfw_r_to_l: scfw_r_to_l {
			label = "&SCFW_R_TO_L";
			compatible = "zmk,behavior-macro";
			#binding-cells = < 0x0 >;
			bindings = < &macro_press >, < &kp 0x6070050 >, < &macro_pause_for_release >, < &macro_release >, < &kp 0x6070050 >, < &macro_tap >, < &kp 0x8070006 >;
		};
		scfw_l_to_r: scfw_l_to_r {
			label = "&SCFW_L_TO_R";
			compatible = "zmk,behavior-macro";
			#binding-cells = < 0x0 >;
			bindings = < &macro_press >, < &kp 0x607004f >, < &macro_pause_for_release >, < &macro_release >, < &kp 0x607004f >, < &macro_tap >, < &kp 0x8070006 >;
		};
		bt_disc_0: bt_disc_0 {
			label = "BT_DISC_0";
			compatible = "zmk,behavior-macro";
			#binding-cells = < 0x0 >;
			bindings = < &macro_tap >, < &bt 0x5 0x1 >, < &macro_wait_time 0x14 >, < &macro_tap >, < &bt 0x5 0x2 >, < &macro_wait_time 0x14 >, < &macro_tap >, < &bt 0x5 0x3 >, < &macro_wait_time 0x14 >, < &macro_tap >, < &bt 0x5 0x4 >;
			phandle = < 0x32 >;
		};
		bt_disc_1: bt_disc_1 {
			label = "BT_DISC_1";
			compatible = "zmk,behavior-macro";
			#binding-cells = < 0x0 >;
			bindings = < &macro_tap >, < &bt 0x5 0x0 >, < &macro_wait_time 0x14 >, < &macro_tap >, < &bt 0x5 0x2 >, < &macro_wait_time 0x14 >, < &macro_tap >, < &bt 0x5 0x3 >, < &macro_wait_time 0x14 >, < &macro_tap >, < &bt 0x5 0x4 >;
			phandle = < 0x33 >;
		};
		bt_disc_2: bt_disc_2 {
			label = "BT_DISC_2";
			compatible = "zmk,behavior-macro";
			#binding-cells = < 0x0 >;
			bindings = < &macro_tap >, < &bt 0x5 0x0 >, < &macro_wait_time 0x14 >, < &macro_tap >, < &bt 0x5 0x1 >, < &macro_wait_time 0x14 >, < &macro_tap >, < &bt 0x5 0x3 >, < &macro_wait_time 0x14 >, < &macro_tap >, < &bt 0x5 0x4 >;
			phandle = < 0x34 >;
		};
		bt_disc_3: bt_disc_3 {
			label = "BT_DISC_3";
			compatible = "zmk,behavior-macro";
			#binding-cells = < 0x0 >;
			bindings = < &macro_tap >, < &bt 0x5 0x0 >, < &macro_wait_time 0x14 >, < &macro_tap >, < &bt 0x5 0x1 >, < &macro_wait_time 0x14 >, < &macro_tap >, < &bt 0x5 0x2 >, < &macro_wait_time 0x14 >, < &macro_tap >, < &bt 0x5 0x4 >;
			phandle = < 0x35 >;
		};
		bt_disc_4: bt_disc_4 {
			label = "BT_DISC_4";
			compatible = "zmk,behavior-macro";
			#binding-cells = < 0x0 >;
			bindings = < &macro_tap >, < &bt 0x5 0x0 >, < &macro_wait_time 0x14 >, < &macro_tap >, < &bt 0x5 0x1 >, < &macro_wait_time 0x14 >, < &macro_tap >, < &bt 0x5 0x2 >, < &macro_wait_time 0x14 >, < &macro_tap >, < &bt 0x5 0x3 >;
			phandle = < 0x36 >;
		};
		bt_select_disc_0: bt_select_disc_0 {
			label = "BT_SELECT_DISC_0";
			compatible = "zmk,behavior-macro";
			#binding-cells = < 0x0 >;
			bindings = < &macro_tap >, < &bt_select_c 0x0 >, < &macro_wait_time 0x14 >, < &macro_tap >, < &bt_disc_0 >;
			phandle = < 0x11 >;
		};
		bt_select_disc_1: bt_select_disc_1 {
			label = "BT_SELECT_DISC_1";
			compatible = "zmk,behavior-macro";
			#binding-cells = < 0x0 >;
			bindings = < &macro_tap >, < &bt_select_c 0x1 >, < &macro_wait_time 0x14 >, < &macro_tap >, < &bt_disc_1 >;
			phandle = < 0x14 >;
		};
		bt_select_disc_2: bt_select_disc_2 {
			label = "BT_SELECT_DISC_2";
			compatible = "zmk,behavior-macro";
			#binding-cells = < 0x0 >;
			bindings = < &macro_tap >, < &bt_select_c 0x2 >, < &macro_wait_time 0x14 >, < &macro_tap >, < &bt_disc_2 >;
			phandle = < 0x15 >;
		};
		bt_select_disc_3: bt_select_disc_3 {
			label = "BT_SELECT_DISC_3";
			compatible = "zmk,behavior-macro";
			#binding-cells = < 0x0 >;
			bindings = < &macro_tap >, < &bt_select_c 0x3 >, < &macro_wait_time 0x14 >, < &macro_tap >, < &bt_disc_3 >;
			phandle = < 0x16 >;
		};
		bt_select_disc_4: bt_select_disc_4 {
			label = "BT_SELECT_DISC_4";
			compatible = "zmk,behavior-macro";
			#binding-cells = < 0x0 >;
			bindings = < &macro_tap >, < &bt_select_c 0x4 >, < &macro_wait_time 0x14 >, < &macro_tap >, < &bt_disc_4 >;
			phandle = < 0x17 >;
		};
		bt_select_c: bt_select_c {
			label = "BT_SELECT_C";
			compatible = "zmk,behavior-macro-one-param";
			#binding-cells = < 0x1 >;
			bindings = < &macro_tap >, < &out 0x2 &macro_param_1to2 >, < &macro_wait_time 0xc8 >, < &macro_tap >, < &bt 0x3 0x0 >;
			phandle = < 0x31 >;
		};
		bt_pairing_c: bt_pairing_c {
			label = "BT_PAIRING_C";
			compatible = "zmk,behavior-macro-one-param";
			#binding-cells = < 0x1 >;
			bindings = < &macro_param_1to1 >, < &macro_tap >, < &bt_select_c 0x0 >, < &macro_wait_time 0x14 >, < &macro_tap >, < &bt 0x0 0x0 >;
			phandle = < 0x13 >;
		};
		pfind: pfind {
			label = "&PFIND";
			compatible = "zmk,behavior-macro";
			#binding-cells = < 0x0 >;
			bindings = < &macro_tap >, < &kp 0x8070009 >, < &macro_wait_time 0xa >, < &macro_tap >, < &kp 0x8070019 >;
			phandle = < 0x1e >;
		};
		gpfind: gpfind {
			label = "&GPFIND";
			compatible = "zmk,behavior-macro";
			#binding-cells = < 0x0 >;
			bindings = < &macro_tap >, < &kp 0xa070009 >, < &macro_wait_time 0xa >, < &macro_tap >, < &kp 0x8070019 >;
			phandle = < 0x1f >;
		};
	};
	combos {
		compatible = "zmk,combos";
		rcomboact_comb_wf {
			timeout-ms = < 0x7d0 >;
			bindings = < &kp 0x70029 >;
			key-positions = < 0x0 0x1 0x2 >;
			slow-release;
			layers = < 0x0 0x8 0x9 0x7 0x6 0xa 0x1 0x3 0x4 0x2 >;
		};
		rcomboact_comb_fp {
			timeout-ms = < 0x7d0 >;
			bindings = < &kp 0x7002c >;
			key-positions = < 0x1 0x2 0x3 >;
			slow-release;
			layers = < 0x0 0x8 0x9 0x7 0x6 0xa 0x1 0x3 0x4 0x2 >;
		};
		rcomboact_comb_pb {
			timeout-ms = < 0x7d0 >;
			bindings = < &kp 0x70028 >;
			key-positions = < 0x3 0x4 >;
			slow-release;
			layers = < 0x0 0x8 0x9 0x7 0x6 0xa 0x1 0x3 0x4 0x2 >;
		};
		rcomboact_comb_pb_2 {
			timeout-ms = < 0x7d0 >;
			bindings = < &kp 0x70028 >;
			key-positions = < 0xc 0x3 0xd >;
			slow-release;
			layers = < 0x0 0x8 0x9 0x7 0x6 0xa 0x1 0x3 0x4 0x2 >;
		};
		rcomboact_comb_tg_2 {
			timeout-ms = < 0x7d0 >;
			bindings = < &kp 0x7002b >;
			key-positions = < 0x16 0xd 0x17 >;
			slow-release;
			layers = < 0x0 0x8 0x9 0x7 0x6 0xa 0x1 0x3 0x4 0x2 >;
		};
		rcomboact_comb_tg {
			timeout-ms = < 0x7d0 >;
			bindings = < &kp 0x7002b >;
			key-positions = < 0x17 0x18 >;
			slow-release;
			layers = < 0x0 0x8 0x9 0x7 0x6 0xa 0x1 0x3 0x4 0x2 >;
		};
		rcomboact_comb_cd {
			timeout-ms = < 0x7d0 >;
			bindings = < &kp 0x7002a >;
			key-positions = < 0x15 0x16 0x17 >;
			slow-release;
			layers = < 0x0 0x8 0x9 0x7 0x6 0xa 0x1 0x3 0x4 0x2 >;
		};
		rcomboact_comb_xc {
			timeout-ms = < 0x7d0 >;
			bindings = < &kp 0x7004c >;
			key-positions = < 0x14 0x15 0x16 >;
			slow-release;
			layers = < 0x0 0x8 0x9 0x7 0x6 0xa 0x1 0x3 0x4 0x2 >;
		};
		lcombo_comb_gv {
			timeout-ms = < 0x1f4 >;
			bindings = < &kp 0x7002d >;
			key-positions = < 0xe 0x18 >;
			require-prior-idle-ms = < 0x64 >;
			layers = < 0x0 0x9 0x7 0x6 0x5 0xa 0x1 0x3 0x4 0x2 >;
		};
		lcombo_comb_td {
			timeout-ms = < 0x1f4 >;
			bindings = < &kp 0x70035 >;
			key-positions = < 0xd 0x17 >;
			require-prior-idle-ms = < 0x64 >;
			layers = < 0x0 0x9 0x7 0x6 0x5 0xa 0x1 0x3 0x4 0x2 >;
		};
		lcombo_comb_sc {
			timeout-ms = < 0x1f4 >;
			bindings = < &kp 0x70030 >;
			key-positions = < 0xc 0x16 >;
			require-prior-idle-ms = < 0x64 >;
			layers = < 0x0 0x9 0x7 0x6 0x5 0xa 0x1 0x3 0x4 0x2 >;
		};
		lcombo_comb_rx {
			timeout-ms = < 0x1f4 >;
			bindings = < &kp 0x7002f >;
			key-positions = < 0xb 0x15 >;
			require-prior-idle-ms = < 0x64 >;
			layers = < 0x0 0x9 0x7 0x6 0x5 0xa 0x1 0x3 0x4 0x2 >;
		};
		lcombo_comb_az {
			timeout-ms = < 0x1f4 >;
			bindings = < &kp 0x70031 >;
			key-positions = < 0xa 0x14 >;
			require-prior-idle-ms = < 0x64 >;
			layers = < 0x0 0x9 0x7 0x6 0x5 0xa 0x1 0x3 0x4 0x2 >;
		};
		rcombo_requal {
			timeout-ms = < 0x1f4 >;
			bindings = < &kp 0x7002e >;
			key-positions = < 0xf 0x19 >;
			require-prior-idle-ms = < 0x64 >;
			layers = < 0x0 0x9 0x7 0x6 0xa >;
		};
		rcombo_rsemi {
			timeout-ms = < 0x1f4 >;
			bindings = < &kp 0x70033 >;
			key-positions = < 0x10 0x1a >;
			require-prior-idle-ms = < 0x64 >;
			layers = < 0x0 0x9 0x7 0x6 0xa >;
		};
		rcombo_SEMI {
			timeout-ms = < 0x1f4 >;
			bindings = < &kp 0x70036 >;
			key-positions = < 0x11 0x1b >;
			require-prior-idle-ms = < 0x64 >;
			layers = < 0x0 0x9 0x7 0x6 0xa >;
		};
		rcombo_COLON {
			timeout-ms = < 0x1f4 >;
			bindings = < &kp 0x70037 >;
			key-positions = < 0x12 0x1c >;
			require-prior-idle-ms = < 0x64 >;
			layers = < 0x0 0x9 0x7 0x6 0xa >;
		};
		rcombo_FSLH {
			timeout-ms = < 0x1f4 >;
			bindings = < &kp 0x70038 >;
			key-positions = < 0x13 0x1d >;
			require-prior-idle-ms = < 0x64 >;
			layers = < 0x0 0x9 0x7 0x6 0xa >;
		};
		lcombo_NUM1 {
			timeout-ms = < 0x1f4 >;
			bindings = < &kp 0x7001e >;
			key-positions = < 0x0 0xa >;
			require-prior-idle-ms = < 0x64 >;
			layers = < 0x0 0x9 0x7 0x6 0x5 0xa 0x1 0x3 0x4 0x2 >;
		};
		lcombo_NUM2 {
			timeout-ms = < 0x1f4 >;
			bindings = < &kp 0x7001f >;
			key-positions = < 0x1 0xb >;
			require-prior-idle-ms = < 0x64 >;
			layers = < 0x0 0x9 0x7 0x6 0x5 0xa 0x1 0x3 0x4 0x2 >;
		};
		lcombo_NUM3 {
			timeout-ms = < 0x1f4 >;
			bindings = < &kp 0x70020 >;
			key-positions = < 0x2 0xc >;
			require-prior-idle-ms = < 0x64 >;
			layers = < 0x0 0x9 0x7 0x6 0x5 0xa 0x1 0x3 0x4 0x2 >;
		};
		lcombo_NUM4 {
			timeout-ms = < 0x1f4 >;
			bindings = < &kp 0x70021 >;
			key-positions = < 0x3 0xd >;
			require-prior-idle-ms = < 0x64 >;
			layers = < 0x0 0x9 0x7 0x6 0x5 0xa 0x1 0x3 0x4 0x2 >;
		};
		lcombo_NUM5 {
			timeout-ms = < 0x1f4 >;
			bindings = < &kp 0x70022 >;
			key-positions = < 0x4 0xe >;
			require-prior-idle-ms = < 0x64 >;
			layers = < 0x0 0x9 0x7 0x6 0x5 0xa 0x1 0x3 0x4 0x2 >;
		};
		rcombo_NUM6 {
			timeout-ms = < 0x1f4 >;
			bindings = < &kp 0x70023 >;
			key-positions = < 0x5 0xf >;
			require-prior-idle-ms = < 0x64 >;
			layers = < 0x0 0x9 0x7 0x6 0xa >;
		};
		rcombo_NUM7 {
			timeout-ms = < 0x1f4 >;
			bindings = < &kp 0x70024 >;
			key-positions = < 0x6 0x10 >;
			require-prior-idle-ms = < 0x64 >;
			layers = < 0x0 0x9 0x7 0x6 0xa >;
		};
		rcombo_NUM8 {
			timeout-ms = < 0x1f4 >;
			bindings = < &kp 0x70025 >;
			key-positions = < 0x7 0x11 >;
			require-prior-idle-ms = < 0x64 >;
			layers = < 0x0 0x9 0x7 0x6 0xa >;
		};
		rcombo_NUM9 {
			timeout-ms = < 0x1f4 >;
			bindings = < &kp 0x70026 >;
			key-positions = < 0x8 0x12 >;
			require-prior-idle-ms = < 0x64 >;
			layers = < 0x0 0x9 0x7 0x6 0xa >;
		};
		rcombo_NUM0 {
			timeout-ms = < 0x1f4 >;
			bindings = < &kp 0x70027 >;
			key-positions = < 0x9 0x13 >;
			require-prior-idle-ms = < 0x64 >;
			layers = < 0x0 0x9 0x7 0x6 0xa >;
		};
		rcombomouse_offmouse {
			timeout-ms = < 0x320 >;
			bindings = < &tog_off 0x1 >;
			key-positions = < 0x6 0x7 0x8 >;
		};
		rcombomouse_offmouse2 {
			timeout-ms = < 0x320 >;
			bindings = < &tog_off 0x1 >;
			key-positions = < 0x6 0xf >;
		};
		rcombomouse_offmouse3 {
			timeout-ms = < 0x320 >;
			bindings = < &tog_off 0x1 >;
			key-positions = < 0x7 0x8 >;
		};
		comboda_adj_tog_on {
			timeout-ms = < 0x1f4 >;
			bindings = < &tog_on 0xb >;
			key-positions = < 0x0 0x1 0x2 0x3 >;
			layers = < 0x9 >;
		};
		comboadj_adj_tog_off {
			timeout-ms = < 0x1f4 >;
			bindings = < &tog_off 0xb >;
			key-positions = < 0x0 0x1 0x2 0x3 >;
			layers = < 0xb >;
		};
		c-hr-thumb-arl {
			bindings = < &kp 0x20700e0 >;
			key-positions = < 0x23 0xa 0xb >;
			layers = < 0x0 >;
			slow-release;
			key-positions-first-exclude = < 0x23 >;
			timeout-ms = < 0x7d0 >;
		};
		c-hr-thumb-arsl {
			bindings = < &kp 0x60700e0 >;
			key-positions = < 0x23 0xa 0xb 0xc >;
			layers = < 0x0 >;
			slow-release;
			key-positions-first-exclude = < 0x23 >;
			timeout-ms = < 0x7d0 >;
		};
		c-hr-thumb-arstl {
			bindings = < &kp 0xe0700e0 >;
			key-positions = < 0x23 0xa 0xb 0xc 0xd >;
			layers = < 0x0 >;
			slow-release;
			key-positions-first-exclude = < 0x23 >;
			timeout-ms = < 0x7d0 >;
		};
		c-hr-thumb-artl {
			bindings = < &kp 0x30700e3 >;
			key-positions = < 0x23 0xa 0xb 0xd >;
			layers = < 0x0 >;
			slow-release;
			key-positions-first-exclude = < 0x23 >;
			timeout-ms = < 0x7d0 >;
		};
		c-hr-thumb-astl {
			bindings = < &kp 0x60700e3 >;
			key-positions = < 0x23 0xa 0xd 0xc >;
			layers = < 0x0 >;
			slow-release;
			key-positions-first-exclude = < 0x23 >;
			timeout-ms = < 0x7d0 >;
		};
		c-hr-thumb-rstl {
			bindings = < &kp 0x50700e3 >;
			key-positions = < 0x23 0xd 0xc 0xb >;
			layers = < 0x0 >;
			slow-release;
			key-positions-first-exclude = < 0x23 >;
			timeout-ms = < 0x7d0 >;
		};
		c-hr-thumb-atl {
			bindings = < &kp 0x20700e3 >;
			key-positions = < 0x23 0xd 0xa >;
			layers = < 0x0 >;
			slow-release;
			key-positions-first-exclude = < 0x23 >;
			timeout-ms = < 0x7d0 >;
		};
		c-hr-thumb-stl {
			bindings = < &kp 0x40700e3 >;
			key-positions = < 0x23 0xc 0xd >;
			layers = < 0x0 >;
			slow-release;
			key-positions-first-exclude = < 0x23 >;
			timeout-ms = < 0x7d0 >;
		};
		c-hr-thumb-rsl {
			bindings = < &kp 0x10700e2 >;
			key-positions = < 0x23 0xc 0xb >;
			layers = < 0x0 >;
			slow-release;
			key-positions-first-exclude = < 0x23 >;
			timeout-ms = < 0x7d0 >;
		};
		c-hr-thumb-rtl {
			bindings = < &kp 0x10700e3 >;
			key-positions = < 0x23 0xd 0xb >;
			layers = < 0x0 >;
			slow-release;
			key-positions-first-exclude = < 0x23 >;
			timeout-ms = < 0x7d0 >;
		};
		c-hr-thumb-asl {
			bindings = < &kp 0x20700e2 >;
			key-positions = < 0x23 0xa 0xc >;
			layers = < 0x0 >;
			slow-release;
			key-positions-first-exclude = < 0x23 >;
			timeout-ms = < 0x7d0 >;
		};
		c-hr-thumb-arr {
			bindings = < &kp 0x20700e0 >;
			key-positions = < 0x23 0x13 0x12 >;
			layers = < 0x0 >;
			slow-release;
			key-positions-first-exclude = < 0x23 >;
			timeout-ms = < 0x7d0 >;
		};
		c-hr-thumb-arsr {
			bindings = < &kp 0x60700e0 >;
			key-positions = < 0x23 0x13 0x12 0x11 >;
			layers = < 0x0 >;
			slow-release;
			key-positions-first-exclude = < 0x23 >;
			timeout-ms = < 0x7d0 >;
		};
		c-hr-thumb-arstr {
			bindings = < &kp 0xe0700e0 >;
			key-positions = < 0x23 0x13 0x12 0x11 0x10 >;
			layers = < 0x0 >;
			slow-release;
			key-positions-first-exclude = < 0x23 >;
			timeout-ms = < 0x7d0 >;
		};
		c-hr-thumb-artr {
			bindings = < &kp 0x30700e3 >;
			key-positions = < 0x23 0x13 0x12 0x10 >;
			layers = < 0x0 >;
			slow-release;
			key-positions-first-exclude = < 0x23 >;
			timeout-ms = < 0x7d0 >;
		};
		c-hr-thumb-astr {
			bindings = < &kp 0x60700e3 >;
			key-positions = < 0x23 0x13 0x10 0x11 >;
			layers = < 0x0 >;
			slow-release;
			key-positions-first-exclude = < 0x23 >;
			timeout-ms = < 0x7d0 >;
		};
		c-hr-thumb-rstr {
			bindings = < &kp 0x50700e3 >;
			key-positions = < 0x23 0x10 0x11 0x12 >;
			layers = < 0x0 >;
			slow-release;
			key-positions-first-exclude = < 0x23 >;
			timeout-ms = < 0x7d0 >;
		};
		c-hr-thumb-atr {
			bindings = < &kp 0x20700e3 >;
			key-positions = < 0x23 0x10 0x13 >;
			layers = < 0x0 >;
			slow-release;
			key-positions-first-exclude = < 0x23 >;
			timeout-ms = < 0x7d0 >;
		};
		c-hr-thumb-str {
			bindings = < &kp 0x40700e3 >;
			key-positions = < 0x23 0x11 0x10 >;
			layers = < 0x0 >;
			slow-release;
			key-positions-first-exclude = < 0x23 >;
			timeout-ms = < 0x7d0 >;
		};
		c-hr-thumb-rsr {
			bindings = < &kp 0x10700e2 >;
			key-positions = < 0x23 0x11 0x12 >;
			layers = < 0x0 >;
			slow-release;
			key-positions-first-exclude = < 0x23 >;
			timeout-ms = < 0x7d0 >;
		};
		c-hr-thumb-rtr {
			bindings = < &kp 0x10700e3 >;
			key-positions = < 0x23 0x10 0x12 >;
			layers = < 0x0 >;
			slow-release;
			key-positions-first-exclude = < 0x23 >;
			timeout-ms = < 0x7d0 >;
		};
		c-hr-thumb-asr {
			bindings = < &kp 0x20700e2 >;
			key-positions = < 0x23 0x13 0x11 >;
			layers = < 0x0 >;
			slow-release;
			key-positions-first-exclude = < 0x23 >;
			timeout-ms = < 0x7d0 >;
		};
		cbks_0 {
			timeout-ms = < 0x7d0 >;
			bindings = < &kp 0x407001e >;
			key-positions = < 0x0 0x22 >;
			key-positions-leader = < 0x0 >;
			key-positions-first-exclude = < 0x22 >;
			layers = < 0x0 0x9 0x7 0x6 0xa >;
		};
		cbkl_2 {
			timeout-ms = < 0x7d0 >;
			bindings = < &mo 0xa >;
			key-positions = < 0x2 0x22 >;
			key-positions-leader = < 0x2 >;
			key-positions-first-exclude = < 0x22 >;
			slow-release;
			layers = < 0x0 0x9 0x7 0x6 0xa >;
		};
		cbkl_3 {
			timeout-ms = < 0x7d0 >;
			bindings = < &mo 0xc >;
			key-positions = < 0x3 0x22 >;
			key-positions-leader = < 0x3 >;
			key-positions-first-exclude = < 0x22 >;
			slow-release;
			layers = < 0x0 0x9 0x7 0x6 0xa >;
		};
		cbkl_4 {
			timeout-ms = < 0x7d0 >;
			bindings = < &mo 0x9 >;
			key-positions = < 0x4 0x22 >;
			key-positions-leader = < 0x4 >;
			key-positions-first-exclude = < 0x22 >;
			slow-release;
			layers = < 0x0 0x9 0x7 0x6 0xa >;
		};
		cbks_7 {
			timeout-ms = < 0x7d0 >;
			bindings = < &mc_bkctilde 0x70018 >;
			key-positions = < 0x7 0x22 >;
			key-positions-leader = < 0x7 >;
			key-positions-first-exclude = < 0x22 >;
			layers = < 0x0 0x9 0x7 0x6 0xa >;
		};
		cbks_10 {
			timeout-ms = < 0x7d0 >;
			bindings = < &mc_bkctilde 0x70004 >;
			key-positions = < 0xa 0x22 >;
			key-positions-leader = < 0xa >;
			key-positions-first-exclude = < 0x22 >;
			layers = < 0x0 0x9 0x7 0x6 0xa >;
		};
		cbks_14 {
			timeout-ms = < 0x7d0 >;
			bindings = < &caps_word >;
			key-positions = < 0xe 0x22 >;
			key-positions-leader = < 0xe >;
			key-positions-first-exclude = < 0x22 >;
			layers = < 0x0 0x9 0x7 0x6 0xa >;
		};
		cbks_16 {
			timeout-ms = < 0x7d0 >;
			bindings = < &mc_ennesd 0x70011 >;
			key-positions = < 0x10 0x22 >;
			key-positions-leader = < 0x10 >;
			key-positions-first-exclude = < 0x22 >;
			layers = < 0x0 0x9 0x7 0x6 0xa >;
		};
		cbks_17 {
			timeout-ms = < 0x7d0 >;
			bindings = < &mc_bkctilde 0x70008 >;
			key-positions = < 0x11 0x22 >;
			key-positions-leader = < 0x11 >;
			key-positions-first-exclude = < 0x22 >;
			layers = < 0x0 0x9 0x7 0x6 0xa >;
		};
		cbks_18 {
			timeout-ms = < 0x7d0 >;
			bindings = < &mc_bkctilde 0x7000c >;
			key-positions = < 0x12 0x22 >;
			key-positions-leader = < 0x12 >;
			key-positions-first-exclude = < 0x22 >;
			layers = < 0x0 0x9 0x7 0x6 0xa >;
		};
		cbks_19 {
			timeout-ms = < 0x7d0 >;
			bindings = < &mc_bkctilde 0x70012 >;
			key-positions = < 0x13 0x22 >;
			key-positions-leader = < 0x13 >;
			key-positions-first-exclude = < 0x22 >;
			layers = < 0x0 0x9 0x7 0x6 0xa >;
		};
		cbkl_20 {
			timeout-ms = < 0x7d0 >;
			bindings = < &mo 0x9 >, < &td_find_s_ht 0x70004 0x8070009 >;
			key-positions = < 0x14 0x22 >;
			key-positions-leader = < 0x14 >;
			key-positions-first-exclude = < 0x22 >;
			slow-release;
			layers = < 0x0 0x9 0x7 0x6 0xa >;
		};
		cbkl_21 {
			timeout-ms = < 0x7d0 >;
			bindings = < &mo 0x9 >, < &td_find_g_ht 0x70004 0xa070009 >;
			key-positions = < 0x15 0x22 >;
			key-positions-leader = < 0x15 >;
			key-positions-first-exclude = < 0x22 >;
			slow-release;
			layers = < 0x0 0x9 0x7 0x6 0xa >;
		};
		cbkl_22 {
			timeout-ms = < 0x7d0 >;
			bindings = < &mo 0x9 >, < &lrlMo 0x607000b 0x6070045 >;
			key-positions = < 0x16 0x22 >;
			key-positions-leader = < 0x16 >;
			key-positions-first-exclude = < 0x22 >;
			slow-release;
			layers = < 0x0 0x9 0x7 0x6 0xa >;
		};
		cbkl_23 {
			timeout-ms = < 0x7d0 >;
			bindings = < &mo 0x9 >, < &kp 0x307002d >;
			key-positions = < 0x17 0x22 >;
			key-positions-leader = < 0x17 >;
			key-positions-first-exclude = < 0x22 >;
			slow-release;
			layers = < 0x0 0x9 0x7 0x6 0xa >;
		};
		cbkl_24 {
			timeout-ms = < 0x7d0 >;
			bindings = < &mo 0x9 >, < &kp 0x107002d >;
			key-positions = < 0x18 0x22 >;
			key-positions-leader = < 0x18 >;
			key-positions-first-exclude = < 0x22 >;
			slow-release;
			layers = < 0x0 0x9 0x7 0x6 0xa >;
		};
		cbks_29 {
			timeout-ms = < 0x7d0 >;
			bindings = < &kp 0x6070038 >;
			key-positions = < 0x1d 0x22 >;
			key-positions-leader = < 0x1d >;
			key-positions-first-exclude = < 0x22 >;
			layers = < 0x0 0x9 0x7 0x6 0xa >;
		};
		ctab_0 {
			timeout-ms = < 0x7d0 >;
			bindings = < &mo 0x5 >, < &kp 0x7001e >;
			key-positions = < 0x0 0x23 >;
			key-positions-first-exclude = < 0x23 >;
			key-positions-leader = < 0x0 >;
			slow-release;
			layers = < 0x0 0x9 0x7 0x6 0xa >;
		};
		ctab_1 {
			timeout-ms = < 0x7d0 >;
			bindings = < &mo 0x5 >, < &kp 0x7001f >;
			key-positions = < 0x1 0x23 >;
			key-positions-first-exclude = < 0x23 >;
			key-positions-leader = < 0x1 >;
			slow-release;
			layers = < 0x0 0x9 0x7 0x6 0xa >;
		};
		ctab_2 {
			timeout-ms = < 0x7d0 >;
			bindings = < &mo 0x5 >, < &kp 0x70020 >;
			key-positions = < 0x2 0x23 >;
			key-positions-first-exclude = < 0x23 >;
			key-positions-leader = < 0x2 >;
			slow-release;
			layers = < 0x0 0x9 0x7 0x6 0xa >;
		};
		ctab_3 {
			timeout-ms = < 0x7d0 >;
			bindings = < &mo 0x5 >, < &kp 0x70021 >;
			key-positions = < 0x3 0x23 >;
			key-positions-first-exclude = < 0x23 >;
			key-positions-leader = < 0x3 >;
			slow-release;
			layers = < 0x0 0x9 0x7 0x6 0xa >;
		};
		ctab_4 {
			timeout-ms = < 0x7d0 >;
			bindings = < &mo 0x5 >, < &kp 0x70022 >;
			key-positions = < 0x4 0x23 >;
			key-positions-first-exclude = < 0x23 >;
			key-positions-leader = < 0x4 >;
			slow-release;
			layers = < 0x0 0x9 0x7 0x6 0xa >;
		};
		ctab_5 {
			timeout-ms = < 0x7d0 >;
			bindings = < &mo 0x5 >, < &kp 0x70023 >;
			key-positions = < 0x5 0x23 >;
			key-positions-first-exclude = < 0x23 >;
			key-positions-leader = < 0x5 >;
			slow-release;
			layers = < 0x0 0x9 0x7 0x6 0xa >;
		};
		ctab_6 {
			timeout-ms = < 0x7d0 >;
			bindings = < &mo 0x5 >, < &kp 0x70024 >;
			key-positions = < 0x6 0x23 >;
			key-positions-first-exclude = < 0x23 >;
			key-positions-leader = < 0x6 >;
			slow-release;
			layers = < 0x0 0x9 0x7 0x6 0xa >;
		};
		ctab_7 {
			timeout-ms = < 0x7d0 >;
			bindings = < &mo 0x5 >, < &kp 0x70025 >;
			key-positions = < 0x7 0x23 >;
			key-positions-first-exclude = < 0x23 >;
			key-positions-leader = < 0x7 >;
			slow-release;
			layers = < 0x0 0x9 0x7 0x6 0xa >;
		};
		ctab_8 {
			timeout-ms = < 0x7d0 >;
			bindings = < &mo 0x5 >, < &kp 0x70026 >;
			key-positions = < 0x8 0x23 >;
			key-positions-first-exclude = < 0x23 >;
			key-positions-leader = < 0x8 >;
			slow-release;
			layers = < 0x0 0x9 0x7 0x6 0xa >;
		};
		ctab_9 {
			timeout-ms = < 0x7d0 >;
			bindings = < &mo 0x5 >, < &kp 0x70027 >;
			key-positions = < 0x9 0x23 >;
			key-positions-first-exclude = < 0x23 >;
			key-positions-leader = < 0x9 >;
			slow-release;
			layers = < 0x0 0x9 0x7 0x6 0xa >;
		};
		ctabd_10 {
			timeout-ms = < 0x7d0 >;
			bindings = < &mhr 0x700e1 >;
			key-positions = < 0xa 0x23 >;
			key-positions-first-exclude = < 0x23 >;
			key-positions-leader = < 0xa >;
			slow-release;
			layers = < 0x0 0x9 0x7 0x6 0xa >;
		};
		ctabd_11 {
			timeout-ms = < 0x7d0 >;
			bindings = < &mhr 0x700e0 >;
			key-positions = < 0xb 0x23 >;
			key-positions-first-exclude = < 0x23 >;
			key-positions-leader = < 0xb >;
			slow-release;
			layers = < 0x0 0x9 0x7 0x6 0xa >;
		};
		ctabd_12 {
			timeout-ms = < 0x7d0 >;
			bindings = < &mhr 0x700e2 >;
			key-positions = < 0xc 0x23 >;
			key-positions-first-exclude = < 0x23 >;
			key-positions-leader = < 0xc >;
			slow-release;
			layers = < 0x0 0x9 0x7 0x6 0xa >;
		};
		ctabd_13 {
			timeout-ms = < 0x7d0 >;
			bindings = < &mhr 0x700e3 >;
			key-positions = < 0xd 0x23 >;
			key-positions-first-exclude = < 0x23 >;
			key-positions-leader = < 0xd >;
			slow-release;
			layers = < 0x0 0x9 0x7 0x6 0xa >;
		};
		ctabd_14 {
			timeout-ms = < 0x7d0 >;
			bindings = < &kp 0x70039 >;
			key-positions = < 0xe 0x23 >;
			key-positions-first-exclude = < 0x23 >;
			key-positions-leader = < 0xe >;
			slow-release;
			layers = < 0x0 0x9 0x7 0x6 0xa >;
		};
		ctabda_20 {
			timeout-ms = < 0x7d0 >;
			bindings = < &mo 0x9 >, < &td_find_s_ht 0x70004 0x8070009 >;
			key-positions = < 0x14 0x23 >;
			key-positions-first-exclude = < 0x23 >;
			key-positions-leader = < 0x14 >;
			slow-release;
			layers = < 0x0 0x9 0x7 0x6 0xa >;
		};
		ctabda_21 {
			timeout-ms = < 0x7d0 >;
			bindings = < &mo 0x9 >, < &td_find_g_ht 0x70004 0xa070009 >;
			key-positions = < 0x15 0x23 >;
			key-positions-first-exclude = < 0x23 >;
			key-positions-leader = < 0x15 >;
			slow-release;
			layers = < 0x0 0x9 0x7 0x6 0xa >;
		};
		ctabda_22 {
			timeout-ms = < 0x7d0 >;
			bindings = < &mo 0x9 >, < &lrlMo 0x607000b 0x6070045 >;
			key-positions = < 0x16 0x23 >;
			key-positions-first-exclude = < 0x23 >;
			key-positions-leader = < 0x16 >;
			slow-release;
			layers = < 0x0 0x9 0x7 0x6 0xa >;
		};
		ctabda_23 {
			timeout-ms = < 0x7d0 >;
			bindings = < &mo 0x9 >, < &kp 0x307002d >;
			key-positions = < 0x17 0x23 >;
			key-positions-first-exclude = < 0x23 >;
			key-positions-leader = < 0x17 >;
			slow-release;
			layers = < 0x0 0x9 0x7 0x6 0xa >;
		};
		ctabda_24 {
			timeout-ms = < 0x7d0 >;
			bindings = < &mo 0x9 >, < &kp 0x107002d >;
			key-positions = < 0x18 0x23 >;
			key-positions-first-exclude = < 0x23 >;
			key-positions-leader = < 0x18 >;
			slow-release;
			layers = < 0x0 0x9 0x7 0x6 0xa >;
		};
		cent_0 {
			timeout-ms = < 0x7d0 >;
			bindings = < &mo 0x6 >, < 0x4070014 >;
			key-positions = < 0x0 0x24 >;
			key-positions-first-exclude = < 0x24 >;
			key-positions-leader = < 0x0 >;
			slow-release;
			layers = < 0x0 0x9 0x7 0x6 0xa >;
		};
		cent_1 {
			timeout-ms = < 0x7d0 >;
			bindings = < &mo 0x6 >, < 0x407001a >;
			key-positions = < 0x1 0x24 >;
			key-positions-first-exclude = < 0x24 >;
			key-positions-leader = < 0x1 >;
			slow-release;
			layers = < 0x0 0x9 0x7 0x6 0xa >;
		};
		cent_2 {
			timeout-ms = < 0x7d0 >;
			bindings = < &mo 0x6 >, < 0x4070009 >;
			key-positions = < 0x2 0x24 >;
			key-positions-first-exclude = < 0x24 >;
			key-positions-leader = < 0x2 >;
			slow-release;
			layers = < 0x0 0x9 0x7 0x6 0xa >;
		};
		cent_3 {
			timeout-ms = < 0x7d0 >;
			bindings = < &mo 0x6 >, < 0x4070013 >;
			key-positions = < 0x3 0x24 >;
			key-positions-first-exclude = < 0x24 >;
			key-positions-leader = < 0x3 >;
			slow-release;
			layers = < 0x0 0x9 0x7 0x6 0xa >;
		};
		cent_4 {
			timeout-ms = < 0x7d0 >;
			bindings = < &mo 0x6 >, < 0x4070005 >;
			key-positions = < 0x4 0x24 >;
			key-positions-first-exclude = < 0x24 >;
			key-positions-leader = < 0x4 >;
			slow-release;
			layers = < 0x0 0x9 0x7 0x6 0xa >;
		};
		cent_5 {
			timeout-ms = < 0x7d0 >;
			bindings = < &mo 0x6 >, < 0x407000d >;
			key-positions = < 0x5 0x24 >;
			key-positions-first-exclude = < 0x24 >;
			key-positions-leader = < 0x5 >;
			slow-release;
			layers = < 0x0 0x9 0x7 0x6 0xa >;
		};
		cent_6 {
			timeout-ms = < 0x7d0 >;
			bindings = < &mo 0x6 >, < 0x407000f >;
			key-positions = < 0x6 0x24 >;
			key-positions-first-exclude = < 0x24 >;
			key-positions-leader = < 0x6 >;
			slow-release;
			layers = < 0x0 0x9 0x7 0x6 0xa >;
		};
		cent_7 {
			timeout-ms = < 0x7d0 >;
			bindings = < &mo 0x6 >, < 0x4070018 >;
			key-positions = < 0x7 0x24 >;
			key-positions-first-exclude = < 0x24 >;
			key-positions-leader = < 0x7 >;
			slow-release;
			layers = < 0x0 0x9 0x7 0x6 0xa >;
		};
		cent_8 {
			timeout-ms = < 0x7d0 >;
			bindings = < &mo 0x6 >, < 0x407001c >;
			key-positions = < 0x8 0x24 >;
			key-positions-first-exclude = < 0x24 >;
			key-positions-leader = < 0x8 >;
			slow-release;
			layers = < 0x0 0x9 0x7 0x6 0xa >;
		};
		cent_9 {
			timeout-ms = < 0x7d0 >;
			bindings = < &mo 0x6 >, < 0x4070034 >;
			key-positions = < 0x9 0x24 >;
			key-positions-first-exclude = < 0x24 >;
			key-positions-leader = < 0x9 >;
			slow-release;
			layers = < 0x0 0x9 0x7 0x6 0xa >;
		};
		cent_10 {
			timeout-ms = < 0x7d0 >;
			bindings = < &mo 0x6 >, < 0x4070004 >;
			key-positions = < 0xa 0x24 >;
			key-positions-first-exclude = < 0x24 >;
			key-positions-leader = < 0xa >;
			slow-release;
			layers = < 0x0 0x9 0x7 0x6 0xa >;
		};
		cent_11 {
			timeout-ms = < 0x7d0 >;
			bindings = < &mo 0x6 >, < 0x4070015 >;
			key-positions = < 0xb 0x24 >;
			key-positions-first-exclude = < 0x24 >;
			key-positions-leader = < 0xb >;
			slow-release;
			layers = < 0x0 0x9 0x7 0x6 0xa >;
		};
		cent_12 {
			timeout-ms = < 0x7d0 >;
			bindings = < &mo 0x6 >, < 0x4070016 >;
			key-positions = < 0xc 0x24 >;
			key-positions-first-exclude = < 0x24 >;
			key-positions-leader = < 0xc >;
			slow-release;
			layers = < 0x0 0x9 0x7 0x6 0xa >;
		};
		cent_13 {
			timeout-ms = < 0x7d0 >;
			bindings = < &mo 0x6 >, < 0x4070017 >;
			key-positions = < 0xd 0x24 >;
			key-positions-first-exclude = < 0x24 >;
			key-positions-leader = < 0xd >;
			slow-release;
			layers = < 0x0 0x9 0x7 0x6 0xa >;
		};
		cent_14 {
			timeout-ms = < 0x7d0 >;
			bindings = < &mo 0x6 >, < 0x407000a >;
			key-positions = < 0xe 0x24 >;
			key-positions-first-exclude = < 0x24 >;
			key-positions-leader = < 0xe >;
			slow-release;
			layers = < 0x0 0x9 0x7 0x6 0xa >;
		};
		cent_15 {
			timeout-ms = < 0x7d0 >;
			bindings = < &mo 0x6 >, < 0x4070010 >;
			key-positions = < 0xf 0x24 >;
			key-positions-first-exclude = < 0x24 >;
			key-positions-leader = < 0xf >;
			slow-release;
			layers = < 0x0 0x9 0x7 0x6 0xa >;
		};
		cent_16 {
			timeout-ms = < 0x7d0 >;
			bindings = < &mo 0x6 >, < 0x4070011 >;
			key-positions = < 0x10 0x24 >;
			key-positions-first-exclude = < 0x24 >;
			key-positions-leader = < 0x10 >;
			slow-release;
			layers = < 0x0 0x9 0x7 0x6 0xa >;
		};
		cent_17 {
			timeout-ms = < 0x7d0 >;
			bindings = < &mo 0x6 >, < 0x4070008 >;
			key-positions = < 0x11 0x24 >;
			key-positions-first-exclude = < 0x24 >;
			key-positions-leader = < 0x11 >;
			slow-release;
			layers = < 0x0 0x9 0x7 0x6 0xa >;
		};
		cent_18 {
			timeout-ms = < 0x7d0 >;
			bindings = < &mo 0x6 >, < 0x407000c >;
			key-positions = < 0x12 0x24 >;
			key-positions-first-exclude = < 0x24 >;
			key-positions-leader = < 0x12 >;
			slow-release;
			layers = < 0x0 0x9 0x7 0x6 0xa >;
		};
		cent_19 {
			timeout-ms = < 0x7d0 >;
			bindings = < &mo 0x6 >, < 0x4070012 >;
			key-positions = < 0x13 0x24 >;
			key-positions-first-exclude = < 0x24 >;
			key-positions-leader = < 0x13 >;
			slow-release;
			layers = < 0x0 0x9 0x7 0x6 0xa >;
		};
		cent_20 {
			timeout-ms = < 0x7d0 >;
			bindings = < &mo 0x6 >, < 0x407001d >;
			key-positions = < 0x14 0x24 >;
			key-positions-first-exclude = < 0x24 >;
			key-positions-leader = < 0x14 >;
			slow-release;
			layers = < 0x0 0x9 0x7 0x6 0xa >;
		};
		cent_21 {
			timeout-ms = < 0x7d0 >;
			bindings = < &mo 0x6 >, < 0x407001b >;
			key-positions = < 0x15 0x24 >;
			key-positions-first-exclude = < 0x24 >;
			key-positions-leader = < 0x15 >;
			slow-release;
			layers = < 0x0 0x9 0x7 0x6 0xa >;
		};
		cent_22 {
			timeout-ms = < 0x7d0 >;
			bindings = < &mo 0x6 >, < 0x4070006 >;
			key-positions = < 0x16 0x24 >;
			key-positions-first-exclude = < 0x24 >;
			key-positions-leader = < 0x16 >;
			slow-release;
			layers = < 0x0 0x9 0x7 0x6 0xa >;
		};
		cent_23 {
			timeout-ms = < 0x7d0 >;
			bindings = < &mo 0x6 >, < 0x4070007 >;
			key-positions = < 0x17 0x24 >;
			key-positions-first-exclude = < 0x24 >;
			key-positions-leader = < 0x17 >;
			slow-release;
			layers = < 0x0 0x9 0x7 0x6 0xa >;
		};
		cent_24 {
			timeout-ms = < 0x7d0 >;
			bindings = < &mo 0x6 >, < 0x4070019 >;
			key-positions = < 0x18 0x24 >;
			key-positions-first-exclude = < 0x24 >;
			key-positions-leader = < 0x18 >;
			slow-release;
			layers = < 0x0 0x9 0x7 0x6 0xa >;
		};
		cent_25 {
			timeout-ms = < 0x7d0 >;
			bindings = < &mo 0x6 >, < 0x407000e >;
			key-positions = < 0x19 0x24 >;
			key-positions-first-exclude = < 0x24 >;
			key-positions-leader = < 0x19 >;
			slow-release;
			layers = < 0x0 0x9 0x7 0x6 0xa >;
		};
		cent_26 {
			timeout-ms = < 0x7d0 >;
			bindings = < &mo 0x6 >, < 0x407000b >;
			key-positions = < 0x1a 0x24 >;
			key-positions-first-exclude = < 0x24 >;
			key-positions-leader = < 0x1a >;
			slow-release;
			layers = < 0x0 0x9 0x7 0x6 0xa >;
		};
		cent_27 {
			timeout-ms = < 0x7d0 >;
			bindings = < &mo 0x6 >, < 0x4070036 >;
			key-positions = < 0x1b 0x24 >;
			key-positions-first-exclude = < 0x24 >;
			key-positions-leader = < 0x1b >;
			slow-release;
			layers = < 0x0 0x9 0x7 0x6 0xa >;
		};
		cent_28 {
			timeout-ms = < 0x7d0 >;
			bindings = < &mo 0x6 >, < 0x4070037 >;
			key-positions = < 0x1c 0x24 >;
			key-positions-first-exclude = < 0x24 >;
			key-positions-leader = < 0x1c >;
			slow-release;
			layers = < 0x0 0x9 0x7 0x6 0xa >;
		};
		cent_29 {
			timeout-ms = < 0x7d0 >;
			bindings = < &mo 0x6 >, < 0x4070038 >;
			key-positions = < 0x1d 0x24 >;
			key-positions-first-exclude = < 0x24 >;
			key-positions-leader = < 0x1d >;
			slow-release;
			layers = < 0x0 0x9 0x7 0x6 0xa >;
		};
	};
	keymap {
		compatible = "zmk,keymap";
		base_layer {
			label = "BASE";
			bindings = < &kp 0x70014 &kp 0x7001a &kp 0x70009 &kp 0x70013 &kp 0x70005 &kp 0x7000d &kp 0x7000f &kp 0x70018 &kp 0x7001c &kp 0x70034 &hml 0x700e1 0x70004 &hml 0x700e0 0x70015 &hml 0x700e2 0x70016 &hml 0x700e3 0x70017 &kp 0x7000a &kp 0x70010 &hmr 0x700e7 0x70011 &hmr 0x700e6 0x70008 &hmr 0x700e4 0x7000c &hmr 0x700e5 0x70012 &kp 0x7001d &kp 0x7001b &kp 0x70006 &kp 0x70007 &kp 0x70019 &kp 0x7000e &kp 0x7000b &kp 0x70036 &kp 0x70037 &kp 0x70038 &kp 0x700e0 &trans &trans &trans &lm_homerow_short 0x700e1 0x7002a &lm_homerow_short 0x700e3 0x7002b &base_th_mo_kp_hp 0x6 0x70028 &spacelm 0x5 0x7002c &kp 0x700e0 >;
		};
		mouse_layer {
			label = "MOUSE";
			bindings = < &kp 0x70014 &kp 0x7001a &kp 0x70009 &kp 0x70013 &kp 0x70005 &trans &trans &kp 0x4 &trans &trans &lrlMo 0x700e1 0x70004 &lrlMo 0x700e0 0x70015 &lrlMo 0x700e2 0x70016 &lrlMo 0x700e3 0x70017 &kp 0x7000a &trans &mkp 0x1 &mo 0x2 &mkp 0x2 &mo 0x3 &kp 0x7001d &kp 0x7001b &kp 0x70006 &kp 0x70007 &kp 0x70019 &trans &tog_off 0x1 &trans &trans &kp 0x70038 &kp 0x700e0 &trans &trans &trans &th_kp_kp_hp 0x700e1 0x7002a &th_kp_kp_hp 0x700e3 0x7002b &th_mo_kp_hp 0x6 0x70028 &space 0x5 0x7002c &kp 0x700e0 >;
		};
		scroll_layer {
			label = "SCROLL";
			bindings = < &kp 0x70014 &kp 0x7001a &kp 0x70009 &kp 0x70013 &kp 0x70005 &trans &trans &kp 0x4 &trans &trans &lrlMo 0x700e1 0x70004 &lrlMo 0x700e0 0x70015 &lrlMo 0x700e2 0x70016 &lrlMo 0x700e3 0x70017 &kp 0x7000a &trans &mkp 0x1 &mo 0x2 &mkp 0x2 &kp 0x700e3 &kp 0x7001d &kp 0x7001b &kp 0x70006 &kp 0x70007 &kp 0x70019 &trans &tog_off 0x1 &trans &trans &kp 0x70038 &kp 0x700e0 &trans &trans &trans &th_kp_kp_hp 0x700e1 0x7002a &th_kp_kp_hp 0x700e3 0x7002b &th_mo_kp_hp 0x6 0x70028 &space 0x5 0x7002c &kp 0x700e0 >;
		};
		snipe_layer {
			label = "SNIPE";
			bindings = < &kp 0x70014 &kp 0x7001a &kp 0x70009 &kp 0x70013 &kp 0x70005 &trans &trans &kp 0x4 &trans &trans &lrlMo 0x700e1 0x70004 &lrlMo 0x700e0 0x70015 &lrlMo 0x700e2 0x70016 &lrlMo 0x700e3 0x70017 &kp 0x7000a &trans &mkp 0x1 &mo 0x2 &mkp 0x2 &mo 0x3 &kp 0x7001d &kp 0x7001b &kp 0x70006 &kp 0x70007 &kp 0x70019 &trans &tog_off 0x1 &trans &trans &kp 0x70038 &kp 0x700e0 &trans &trans &trans &th_kp_kp_hp 0x700e1 0x7002a &th_kp_kp_hp 0x700e3 0x7002b &th_mo_kp_hp 0x6 0x70028 &space 0x5 0x7002c &kp 0x700e0 >;
		};
		warp_layer {
			label = "WARP";
			bindings = < &kp 0x70014 &kp 0x7001a &kp 0x70009 &kp 0x70013 &kp 0x70005 &trans &trans &kp 0x4 &trans &trans &lrlMo 0x700e1 0x70004 &lrlMo 0x700e0 0x70015 &lrlMo 0x700e2 0x70016 &lrlMo 0x700e3 0x70017 &kp 0x7000a &trans &mkp 0x1 &mo 0x2 &mkp 0x2 &mo 0x3 &kp 0x7001d &kp 0x7001b &kp 0x70006 &kp 0x70007 &kp 0x70019 &trans &tog_off 0x1 &trans &trans &kp 0x70038 &kp 0x700e0 &trans &trans &trans &th_kp_kp_hp 0x700e1 0x7002a &th_kp_kp_hp 0x700e3 0x7002b &th_mo_kp_hp 0x6 0x70028 &space 0x5 0x7002c &kp 0x700e0 >;
		};
		lower_layer {
			label = "LOWER";
			bindings = < &kp 0x7001e &kp 0x7001f &kp 0x70020 &kp 0x70021 &kp 0x70022 &kp 0x70023 &kp 0x70024 &kp 0x70025 &kp 0x70026 &kp 0x70027 &lrlMo 0x700e1 0x70004 &lrlMo 0x700e0 0x70015 &lrlMo 0x700e2 0x70016 &lrlMo 0x700e3 0x70017 &kp 0x7000a &kp 0x70010 &kp 0x7004a &kp 0x70052 &kp 0x7004d &kp 0x7004b &kp 0x7001d &kp 0x7001b &kp 0x70006 &kp 0x70007 &kp 0x70019 &kp 0x7002e &kp 0x70050 &kp 0x70051 &kp 0x7004f &kp 0x7004e &kp 0x700e0 &trans &trans &trans &th_kp_kp_hp 0x700e1 0x7002a &th_kp_kp_hp 0x700e3 0x7002b &th_mo_kp_hp 0x6 0x70028 &space 0x5 0x7002c &kp 0x700e0 >;
		};
		raise_layer {
			label = "RAISE";
			bindings = < &kp 0x207001e &kp 0x207001f &kp 0x2070020 &kp 0x2070021 &kp 0x2070022 &kp 0x2070023 &kp 0x2070024 &kp 0x2070025 &kp 0x2070026 &kp 0x2070027 &lrlMo 0x700e1 0x2070031 &lrlMo 0x700e0 0x207002f &lrlMo 0x700e2 0x2070030 &lrlMo 0x700e0 0x2070035 &kp 0x207002d &kp 0x207002e &lrrMo 0x700e7 0x2070033 &lrrMo 0x700e6 0x2070036 &lrrMo 0x700e4 0x2070037 &lrrMo 0x700e5 0x2070038 &kp 0x70031 &kp 0x7002f &kp 0x70030 &kp 0x70035 &kp 0x7002d &kp 0x7002e &kp 0x70033 &kp 0x70036 &kp 0x70037 &kp 0x70038 &kp 0x700e0 &trans &trans &trans &th_kp_kp_hp 0x700e1 0x7002a &th_kp_kp_hp 0x700e3 0x7002b &th_mo_kp_hp 0x6 0x70028 &space 0x5 0x7002c &kp 0x700e0 >;
		};
		layer_homerow {
			label = "HOMEROW";
			bindings = < &kp 0x70014 &kp 0x7001a &kp 0x70009 &kp 0x70013 &kp 0x70005 &kp 0x7000d &kp 0x7000f &kp 0x70018 &kp 0x7001c &kp 0x70034 &lrlMo 0x700e1 0x70004 &lrlMo 0x700e0 0x70015 &lrlMo 0x700e2 0x70016 &lrlMo 0x700e3 0x70017 &kp 0x7000a &kp 0x70010 &lrrMo 0x700e7 0x70011 &lrrMo 0x700e6 0x70008 &lrrMo 0x700e4 0x7000c &lrrMo 0x700e5 0x70012 &kp 0x7001d &kp 0x7001b &kp 0x70006 &kp 0x70007 &kp 0x70019 &kp 0x7000e &kp 0x7000b &kp 0x70036 &kp 0x70037 &kp 0x70038 &kp 0x700e0 &trans &trans &trans &th_kp_kp_hp 0x700e1 0x7002a &th_kp_kp_hp 0x700e3 0x7002b &th_mo_kp_hp 0x6 0x70028 &space 0x5 0x7002c &kp 0x700e0 >;
		};
		layer_navoverr {
			label = "NAVOVERR";
			bindings = < &kp 0x7001e &kp 0x7001f &kp 0x70020 &kp 0x70021 &kp 0x70022 &kp 0x70023 &kp 0x70024 &kp 0x70025 &kp 0x70026 &kp 0x70027 &lrlMo 0x700e1 0x70004 &lrlMo 0x700e0 0x70015 &lrlMo 0x700e2 0x70016 &lrlMo 0x700e3 0x70017 &kp 0x70044 &kp 0x207002e &kp 0x7004a &kp 0x70052 &kp 0x7004d &kp 0x7004b &kp 0x70031 &kp 0x7002f &kp 0x70030 &kp 0x70035 &kp 0x7002d &kp 0x7002e &kp 0x70050 &kp 0x70051 &kp 0x7004f &kp 0x7004e &kp 0x700e0 &trans &trans &trans &th_kp_kp_hp 0x700e1 0x7002a &th_kp_kp_hp 0x700e3 0x7002b &th_mo_kp_hp 0x6 0x70028 &space 0x5 0x7002c &kp 0x700e0 >;
		};
		layer_direcaacc {
			label = "DIRECTACC";
			bindings = < &td_find_s_ht 0x70004 0x8070009 &td_find_g_ht 0x70004 0xa070009 &lrlMo 0x607000b 0x6070045 &kp 0x307002d &kp 0x307002d &kp 0xc00e9 &kp 0xc00b6 &kp 0xc00cd &kp 0xc00b5 &trans &kp 0x700e1 &kp 0x700e0 &kp 0x700e2 &kp 0x700e3 &tdSelectCoppingLR 0x70004 0x70004 &kp 0xc00ea &sk 0x700e7 &sk 0x700e6 &sk 0x700e4 &sk 0x700e5 &td_find_s_ht 0x70004 0x8070009 &td_find_g_ht 0x70004 0xa070009 &lrlMo 0x607000b 0x6070045 &kp 0x307002d &kp 0x107002d &kp 0xc00e2 &kp 0xc0070 &kp 0xc006f &bt_0 &bt_1 &kp 0x700e0 &trans &trans &trans &th_kp_kp_hp 0x700e1 0x7002a &th_kp_kp_hp 0x700e3 0x7002b &th_mo_kp_hp 0x6 0x70028 &space 0x5 0x7002c &kp 0x700e0 >;
		};
		layer_func {
			label = "FUNC";
			bindings = < &kp 0x7003a &kp 0x7003b &kp 0x7003c &kp 0x7003d &kp 0x7003e &kp 0x7003f &kp 0x70040 &kp 0x70041 &kp 0x70042 &kp 0x70043 &sk 0x700e1 &sk 0x700e0 &sk 0x700e2 &sk 0x700e3 &kp 0x70044 &kp 0x70045 &sk 0x700e7 &sk 0x700e6 &sk 0x700e7 &sk 0x700e5 &sk 0x700e2 &none &none &none &kp 0x70044 &kp 0x70045 &sk 0x700e0 &none &none &none &kp 0x700e0 &trans &trans &trans &th_kp_kp_hp 0x700e1 0x7002a &th_kp_kp_hp 0x700e3 0x7002b &th_mo_kp_hp 0x6 0x70028 &space 0x5 0x7002c &kp 0x700e0 >;
		};
		adjust_layer {
			label = "ADJ";
			bindings = < &bt_0 &bt_1 &bt_2 &bt_3 &bt_4 &trans &trans &trans &trans &trans &out 0x1 &trans &trans &trans &trans &trans &trans &trans &trans &trans &sys_reset &trans &trans &trans &trans &trans &trans &trans &trans &sys_reset &kp 0x700e0 &trans &trans &trans &th_kp_kp_hp 0x700e1 0x7002a &th_kp_kp_hp 0x700e3 0x7002b &th_mo_kp_hp 0x6 0x70028 &space 0x5 0x7002c &kp 0x700e0 >;
		};
		layer_numbers {
			label = "NUMBERS";
			bindings = < &kp 0x207001e &kp 0x207001f &kp 0x2070020 &kp 0x2070021 &kp 0x2070022 &kp 0x7002e &kp 0x70024 &kp 0x70025 &kp 0x70026 &kp 0x2070025 &kp 0x700e1 &kp 0x700e0 &kp 0x700e2 &kp 0x700e3 &kp 0x70036 &kp 0x70037 &kp 0x70021 &kp 0x70022 &kp 0x70023 &kp 0x70027 &kp 0x70031 &kp 0x7002f &kp 0x70030 &kp 0x70035 &kp 0x7002d &kp 0x207002e &kp 0x7001e &kp 0x7001f &kp 0x70020 &kp 0x70038 &kp 0x700e0 &trans &trans &trans &th_kp_kp_hp 0x700e1 0x7002a &th_kp_kp_hp 0x700e3 0x7002b &th_mo_kp_hp 0x6 0x70028 &space 0x5 0x7002c &kp 0x700e0 >;
		};
	};
};
